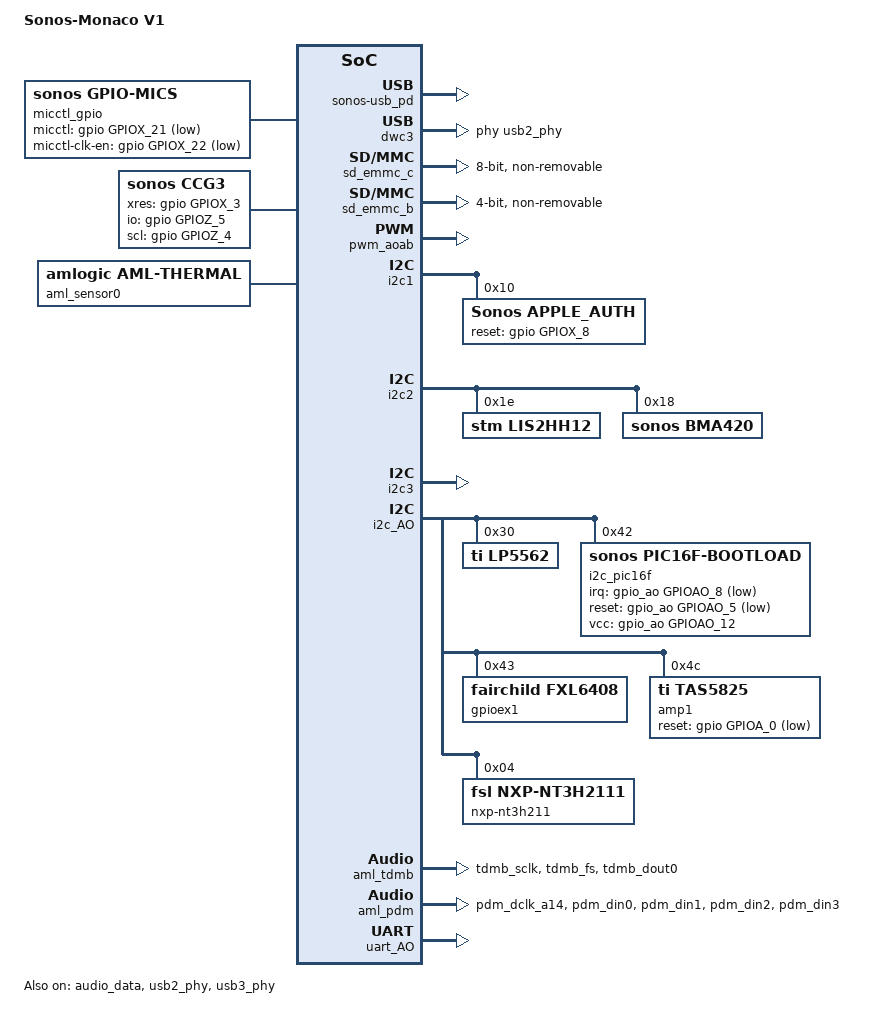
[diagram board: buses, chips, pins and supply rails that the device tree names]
/*
 * Copyright (c) 2019-2020, Sonos, Inc.
 *
 * SPDX-License-Identifier:     GPL-2.0
 */
/* Monaco HW versions
 *      V0 - monaco_v0.dts		- Monaco P0 [Ryles XI]
 *      V1 - monaco.dts			- Monaco P1
 */
/dts-v1/;

#include "a113.dtsi"
#include "../sonos_platform.dtsi"

/ {
	model = "Sonos-Monaco V1";
	amlogic-dt-id = "axg_a113d_skt_v1";
	compatible = "amlogic, axg";
	interrupt-parent = <&gic>;
	#address-cells = <2>;
	#size-cells = <2>;

	sonos-product-id = <0x0d>;

	sonos-platform {
		/* Sonos platform specific values for shared driver source & binaries */
		sonos-ampctl {
			/* Alpine has one amp fault.  It has three control lines.
			 */
			status = "okay";
			hw-inits-index = <1>;
			hw-exits-index = <1>;
			using-i2c-amp;
			ignore-startup-faults;
			allow-auto-recovery;
			supports-boost-control;

			sonos-ampfaults {
				num-faults = <0x01>;
				status = "okay";

				ampfault@0 {
					fault-gpio = <&gpio GPIOA_1 GPIO_ACTIVE_LOW>;
					fault-flags = <IRQ_TYPE_EDGE_FALLING>;
					fault-label = "Amp fault";
				} ;
			} ;
		} ;

		sonos-usb_pd {
			status = "okay";
			hw-inits-index = <1>;
			hw-exits-index = <1>;
		};

		misc-gpio {
			buttons-on-expander;
			no-irq;
		};

		simulated-buttons {
		/* event-sources are offsets from EVTSOURCE_BUTTON_PLAYPAUSE, some generate an event for more than one source */
			join {
				event-sources = <3>;
			};
			mode {
				event-sources = <4>;
			};
			power {
				event-sources= <5>;
				no-repeat-sim;
			};
		};
		thermal-mgmt {
			POWER {
				compatible = "sonos,battery";
				fault-temperature = <68>;
				warn-temperature = <63>;
			};
		};
	} ;

	micctl_gpio:sonos-gpio-micctl {
		compatible = "sonos,gpio-mics";
		micctl-gpio = <&gpio GPIOX_21 GPIO_ACTIVE_LOW>;
		micctl-clk-en = <&gpio GPIOX_22 GPIO_ACTIVE_LOW>;
	};

	micctl@1 {
		compatible = "sonos,micctl";
		micctl-device = <&micctl_gpio>;
	};

	rtc{
		status = "disabled";
	};

	sonos-rtc {
		compatible = "sonos,rtc";
		status = "okay";
	};

	sonos-lla {
		compatible = "sonos,alsa-lla";
		tx_mask = <0x3>;
		rx_mask = <0x7>;
		status = "disabled";
	};

	hrtimer-a113 {
		compatible = "sonos,hrtimer-a113";
		status = "okay";
	};

	ccg3 {
		compatible = "sonos,ccg3";
		xres-gpio = <&gpio GPIOX_3 GPIO_ACTIVE_HIGH>;
		io-gpio   = <&gpio GPIOZ_5 GPIO_ACTIVE_HIGH>;
		scl-gpio  = <&gpio GPIOZ_4 GPIO_ACTIVE_HIGH>;
	};

	aliases {
		serial0 = &uart_AO;
		serial1 = &uart_AO_B;
		serial3 = &uart_A;
	};

	memory@00000000 {
		device_type = "memory";
		linux,usable-memory = <0x0 0x100000 0x0 0x1ff00000>;
	};

	reserved-memory {
		#address-cells = <2>;
		#size-cells = <2>;
		ranges;
		/* global autoconfigured region for contiguous allocations */
		ramoops@0x07400000 {
			compatible = "ramoops";
			reg = <0x0 0x07400000 0x0 0x00100000>;
			record-size = <0x8000>;
			console-size = <0x10000>;
			ftrace-size = <0x2000>;
			pmsg-size = <0x4000>;
		};
		secmon_reserved:linux,secmon {
			compatible = "shared-dma-pool";
			reusable;
			size = <0x0 0x400000>;
			alignment = <0x0 0x400000>;
			alloc-ranges = <0x0 0x05000000 0x0 0x400000>;
		};
		secos_reserved:linux,secos {
			status = "disable";
			compatible = "amlogic, aml_secos_memory";
			reg = <0x0 0x05300000 0x0 0x2000000>;
			no-map;
		};
	};

	ethmac: ethernet@0xff3f0000 {
			compatible = "amlogic, gxbb-eth-dwmac";
			status = "disable";
			reg = <0x0 0xff3f0000 0x0 0x10000
			0x0 0xff634540 0x0 0x8>;
			interrupts = <0 8 1>;
			pinctrl-names = "external_eth_pins";
			pinctrl-0 = <&external_eth_pins>;
			mc_val_internal_phy = <0x1800>;
			mc_val_external_phy = <0x1404>;
			interrupt-names = "macirq";
			clocks = <&clkc CLKID_ETH_CORE>;
			clock-names = "ethclk81";
			internal_phy=<0>;
	};

	aml_sensor0: aml-sensor@0 {
		compatible = "amlogic, aml-thermal";
		device_name = "thermal";
		#thermal-sensor-cells = <1>;
		cooling_devices {
			cpufreq_cool_cluster0 {
				min_state = <1000000>;
				dyn_coeff = <140>;
				cluster_id = <0>;
				node_name = "cpufreq_cool0";
				device_type = "cpufreq";
			};
			cpucore_cool_cluster0 {
				min_state = <1>;
				dyn_coeff = <0>;
				cluster_id = <0>;
				node_name = "cpucore_cool0";
				device_type = "cpucore";
			};
		};
		cpufreq_cool0:cpufreq_cool0 {
			#cooling-cells = <2>; /* min followed by max */
		};
		cpucore_cool0:cpucore_cool0 {
			#cooling-cells = <2>; /* min followed by max */
		};
	};

	remote:rc@0xff808040 {
		status = "disabled";
	};

	thermal-zones {
		soc_thermal {
			polling-delay = <1000>;
			polling-delay-passive = <100>;
			sustainable-power = <1050>;

			thermal-sensors = <&aml_sensor0 3>;

			trips {
				switch_on: trip-point@0 {
					temperature = <70000>;
					hysteresis = <1000>;
					type = "passive";
				};
				control: trip-point@1 {
					temperature = <80000>;
					hysteresis = <1000>;
					type = "passive";
				};
				hot: trip-point@2 {
					temperature = <105000>;
					hysteresis = <5000>;
					type = "hot";
				};
				critical: trip-point@3 {
					temperature = <260000>;
					hysteresis = <1000>;
					type = "critical";
				};
			};

			cooling-maps {
				cpufreq_cooling_map {
					trip = <&control>;
					cooling-device = <&cpufreq_cool0 0 4>;
					contribution = <1024>;
				};
				cpucore_cooling_map {
					trip = <&control>;
					cooling-device = <&cpucore_cool0 0 3>;
					contribution = <1024>;
				};
			};
		};
	};

	dwc3: dwc3@ff500000 {
		compatible = "synopsys, dwc3";
		status = "okay";
		reg = <0x0 0xff500000 0x0 0x100000>;
		interrupts = <0 30 4>;
		usb-phy = <&usb2_phy>, <&usb3_phy>;
		cpu-type = "gxl";
		clock-src = "usb3.0";
		clocks = <&clkc CLKID_USB_GENERAL>;
		clock-names = "dwc_general";
	};

	usb2_phy: usb2phy@ffe09000 {
		compatible = "amlogic, amlogic-new-usb2";
		status = "okay";
		portnum = <4>;
		reg = <0x0 0xffe09000 0x0 0x80>;
	};
	usb3_phy: usb3phy@ffe09080 {
		compatible = "amlogic, amlogic-new-usb3";
		status = "okay";
		portnum = <0>;
		reg = <0x0 0xffe09080 0x0 0x20>;
	};

	dwc2_a {
		compatible = "amlogic, dwc2";
		device_name = "dwc2_a";
		reg = <0x0 0xff400000 0x0 0x40000>;
		status = "disabled";
		interrupts = <0 31 4>;
		pl-periph-id = <0>; /** lm name */
		clock-src = "usb0"; /** clock src */
		port-id = <0>;  /** ref to mach/usb.h */
		port-type = <2>;        /** 0: otg, 1: host, 2: slave */
		port-speed = <0>; /** 0: default, high, 1: full */
		port-config = <0>; /** 0: default */
		/*0:default,1:single,2:incr,3:incr4,4:incr8,5:incr16,6:disable*/
		port-dma = <0>;
		port-id-mode = <0>; /** 0: hardware, 1: sw_host, 2: sw_slave*/
		usb-fifo = <728>;
		cpu-type = "gxl";
		/** 0: normal, 1: otg+dwc3 host only, 2: otg+dwc3 device only*/
		controller-type = <3>;
		phy-reg = <0xffe09000>;
		phy-reg-size = <0xa0>;
		clocks = <&clkc CLKID_USB_GENERAL
			&clkc CLKID_USB1_TO_DDR
			&clkc CLKID_USB1>;
		clock-names = "usb_general",
			"usb1",
			"usb1_to_ddr";
	};

	pcie_A: pcieA@f9800000 {
		compatible = "amlogic, amlogic-pcie", "snps,dw-pcie";
		reg = <0x0 0xf9800000 0x0 0x400000
				0x0 0xff646000 0x0 0x2000
				0x0 0xf9f00000 0x0 0x100000
				0x0 PCIE_PHY_REG 0x0 PCIE_PHY_SIZE
				0x0 PCIE_RESET_REG 0x0 PCIE_RESET_SIZE>;
		reg-names = "elbi", "cfg", "config", "phy", "reset";
		reset-gpio = <&gpio_ao GPIOAO_3 GPIO_ACTIVE_HIGH>;
		interrupts = <0 177 0>, <0 179 0>;
		#interrupt-cells = <1>;
		bus-range = <0x0 0xff>;
		#address-cells = <3>;
		#size-cells = <2>;
		device_type = "pci";
		ranges = <0x82000000 0 0 0x0 0xf9c00000 0 0x00300000>;
			/* non-prefetchable memory */
		num-lanes = <1>;
		pcie-num = <1>;
		speed-mod = <1>; /* gen1 */

		clocks = <&clkc CLKID_USB_GENERAL
				&clkc CLKID_PCIE_PLL
				&clkc CLKID_MIPI_ENABLE_GATE
				&clkc CLKID_MIPI_BANDGAP_GATE
				&clkc CLKID_PCIE_A
				&clkc CLKID_PCIE_CML_EN0>;
		clock-names = "pcie_general",
				"pcie_refpll",
				"pcie_mipi_enable_gate",
				"pcie_mipi_bandgap_gate",
				"pcie",
				"port";
		/*reset-gpio-type 0:Shared pad(no reset)1:OD pad2:Normal pad*/
		gpio-type = <2>;
		status = "disabled";
	};

	pcie_B: pcieB@fa000000 {
		compatible = "amlogic, amlogic-pcie", "snps,dw-pcie";
		reg = <0x0 0xfa000000 0x0 0x400000
				0x0 0xff648000 0x0 0x2000
				0x0 0xfa400000 0x0 0x100000
				0x0 PCIE_PHY_REG 0x0 PCIE_PHY_SIZE
				0x0 PCIE_RESET_REG 0x0 PCIE_RESET_SIZE>;
		reg-names = "elbi", "cfg", "config", "phy", "reset";
		reset-gpio = <&gpio GPIOX_19 GPIO_ACTIVE_HIGH>;
		interrupts = <0 167 0>, <0 169 0>;
		#interrupt-cells = <1>;
		bus-range = <0x0 0xff>;
		#address-cells = <3>;
		#size-cells = <2>;
		device_type = "pci";
		ranges = <0x81000000 0 0 0 0xfa500000 0x0 0x10000
			/* downstream I/O */
			0x82000000 0 0xfa510000 0x0 0xfa510000 0 0x002f0000>;
			/* non-prefetchable memory */
		num-lanes = <1>;
		pcie-num = <2>;
		speed-mod = <1>; /* gen1 */

		clocks = <&clkc CLKID_USB_GENERAL
			&clkc CLKID_PCIE_PLL
			&clkc CLKID_MIPI_ENABLE_GATE
			&clkc CLKID_MIPI_BANDGAP_GATE
			&clkc CLKID_PCIE_B
			&clkc CLKID_PCIE_CML_EN1>;
		clock-names = "pcie_general",
			"pcie_refpll",
			"pcie_mipi_enable_gate",
			"pcie_mipi_bandgap_gate",
			"pcie",
			"port";
		/*reset-gpio-type 0:Shared pad(no reset)1:OD pad2:Normal pad*/
		gpio-type = <0>;
		status = "disabled";
	};

	uart_A: serial@ffd24000 {
		compatible = "amlogic, meson-uart";
		reg = <0x0 0xffd24000 0x0 0x18>;
		interrupts = <0 26 1>;
		status = "disable";
		clocks = <&xtal
			&clkc CLKID_UART0>;
		clock-names = "clk_uart",
			"clk_gate";
		fifosize = < 128 >;
		pinctrl-names = "default";
		pinctrl-0 = <&a_uart_pins>;
	};

	/* Sound iomap */
	aml_snd_iomap {
		compatible = "amlogic, snd-iomap";
		status = "okay";
		#address-cells=<2>;
		#size-cells=<2>;
		ranges;
		pdm_bus {
			reg = <0x0 0xFF632000 0x0 0x2000>;
		};
		audiobus_base {
			reg = <0x0 0xFF642000 0x0 0x2000>;
		};
		audiolocker_base {
			reg = <0x0 0xFF64A000 0x0 0x2000>;
		};
	};
	pdm_codec:dummy{
		#sound-dai-cells = <0>;
		compatible = "amlogic, pdm_dummy_codec";
		status = "okay";
	};
	dummy_codec:dummy{
		#sound-dai-cells = <0>;
		compatible = "amlogic, aml_dummy_codec";
		status = "okay";
	};
	sonos_dummy_codec_dac: dac_dummy_codec {
		#sound-dai-cells = <0>;
		compatible = "Sonos,dummy-codec";
		stream-name = "0-dac";
		rate = <44100>; /* We use 44.1 KHz as the audio output rate */
		format = "S32_LE"; /* We use signed 24-bit little endian samples in a 32-bit word */
		channels = <2>; /* Number of playback channels on Dhuez is 2 */
		status = "okay";
	};
	sonos_dummy_codec_pdm: pdm_dummy_codec {
		#sound-dai-cells = <0>;
		compatible = "Sonos,dummy-codec";
		stream-name = "1-mic";
		rate = <48000>; /* >20 KHz bandwidth required to support "Swap" ultrasonic processing */
		format = "S32_LE"; /* We use signed 24-bit little endian samples in 32-bit words */
		channels = <4>; /* Number of capture channels on Monaco is 4 */
		capture; /* Set the stream direction to capture. Note: Deafult without this boolean flag is playback */
		status = "okay";
	};

	auge_sound {
		compatible = "amlogic, axg-sound-card";
		aml-audio-card,name = "AML-AUGESOUND";

		aml-audio-card,dai-link@1 {
			format = "i2s";
			mclk-fs = <256>;
			continuous-clock;
			frame-inversion;
			bitclock-master = <&aml_tdmb>;
			frame-master = <&aml_tdmb>;
			cpu {
				sound-dai = <&aml_tdmb>;
				dai-tdm-slot-tx-mask = <1 1>;
				dai-tdm-slot-num = <2>;
				dai-tdm-slot-width = <32>;
				system-clock-frequency = <12288000>;
			};
			codec {
				prefix-names = "Sonos i2s out";
				sound-dai = <&sonos_dummy_codec_dac>;
			};
		};

		aml-audio-card,dai-link@3 {
			mclk-fs = <256>;
			cpu {
				sound-dai = <&aml_pdm>;
			};
			codec {
				prefix-names = "Sonos PDM in";
				sound-dai = <&sonos_dummy_codec_pdm>;
			};
		};
	};

	sd_emmc_c: emmc@ffe07000 {
		status = "okay";
		compatible = "amlogic, meson-mmc-axg";
		reg = <0x0 0xffe07000 0x0 0x2000>;
		interrupts = <0 218 1>;
		pinctrl-names = "emmc_clk_cmd_pins", "emmc_all_pins";
		pinctrl-0 = <&emmc_clk_cmd_pins>;
		pinctrl-1 = <&emmc_conf_pull_up &emmc_conf_pull_done>;
		clocks = <&clkc CLKID_SD_EMMC_C>,
			   <&clkc CLKID_SD_EMMC_C_P0_COMP>,
			   <&clkc CLKID_FCLK_DIV2>,
			   <&clkc CLKID_FCLK_DIV5>,
			   <&xtal>;
		clock-names = "core", "clkin0", "clkin1", "clkin2", "xtal";

		bus-width = <8>;
		cap-sd-highspeed;
		cap-mmc-highspeed;
		mmc-ddr-1_8v;
		mmc-hs200-1_8v;

		max-frequency = <200000000>;
		non-removable;
		disable-wp;
		emmc {
			status = "disable";
			pinname = "emmc";
			ocr_avail = <0x200080>; /* VDD voltage 3.3 ~ 3.4 */
			caps = "MMC_CAP_8_BIT_DATA",
				 "MMC_CAP_MMC_HIGHSPEED",
				 "MMC_CAP_SD_HIGHSPEED",
				 "MMC_CAP_NONREMOVABLE",
				 "MMC_CAP_1_8V_DDR",
				 "MMC_CAP_HW_RESET",
				 "MMC_CAP_ERASE",
				 "MMC_CAP_CMD23";
			/* caps2 = "MMC_CAP2_HS200", "MMC_CAP2_HS400"; */
			f_min = <400000>;
			f_max = <200000000>;
			max_req_size = <0x20000>; /* 128KB*/
			gpio_dat3 = <&gpio BOOT_3 GPIO_ACTIVE_HIGH>;
			tx_delay = <0>;
			hw_reset = <&gpio BOOT_9 GPIO_ACTIVE_HIGH>;
			card_type = <1>;
			/* 1:mmc card(include eMMC),
			 * 2:sd card(include tSD)
			 */
		};
	};

	sd_emmc_b:sdio@ffe05000 {
                status = "okay";
                compatible = "amlogic, meson-mmc-axg";
		                reg = <0x0 0xffe05000 0x0 0x2000>;
                interrupts = <0 217 4>;
                pinctrl-names = "sdio_clk_cmd_pins",
                                "sdio_all_pins";
                pinctrl-0 = <&sdio_clk_cmd_pins>;
                pinctrl-1 = <&sdio_all_pins>;
		clocks = <&clkc CLKID_SD_EMMC_B>,
                           <&clkc CLKID_SD_EMMC_B_P0_COMP>,
                           <&clkc CLKID_FCLK_DIV2>,
                           <&clkc CLKID_FCLK_DIV5>,
                           <&xtal>;
                clock-names = "core", "clkin0", "clkin1", "clkin2", "xtal";

                bus-width = <4>;
                cap-sd-highspeed;
                cap-mmc-highspeed;
                max-frequency = <100000000>;
                non-removable;
                disable-wp;
                sdio {
                        pinname = "sdio";
                        ocr_avail = <0x200080>; /**VDD voltage 3.3 ~ 3.4 */
                        caps = "MMC_CAP_4_BIT_DATA",
                                 "MMC_CAP_MMC_HIGHSPEED",
                                 "MMC_CAP_SD_HIGHSPEED",
                                 "MMC_CAP_NONREMOVABLE",
                                 "MMC_CAP_UHS_SDR12",
                                 "MMC_CAP_UHS_SDR25",
                                 "MMC_CAP_UHS_SDR50",
                                 "MMC_CAP_UHS_SDR104",
                                 "MMC_PM_KEEP_POWER",
                                 "MMC_CAP_SDIO_IRQ";
                        f_min = <400000>;
                        f_max = <200000000>;
                        max_req_size = <0x20000>; /**128KB*/
			hw_reset = <&gpio_ao GPIOAO_6 GPIO_ACTIVE_LOW>;
                        card_type = <3>;
                        /* 3:sdio device(ie:sdio-wifi),
                         * 4:SD combo (IO+mem) card
                         */
		};
        };

	/* WiFi */
	mediatek,mt7663-wifi {
                compatible = "mediatek,mt7663_wifi_ctrl";
                interrupts = <&gpio_ao GPIOAO_6 GPIO_ACTIVE_LOW>;
                status = "okay";
	};

	pic16f@0 {
                compatible = "Sonos,pic16f";
                i2c_bus = <2>;
                i2c_reg = <0x42>;
                image-name = "pic16f_v1.hex";
                status = "okay";

		pic16f-gpio@0 {
			icsp-gpio-mclr = <&gpio_ao GPIOAO_5 GPIO_ACTIVE_HIGH>;
			icsp-gpio-data = <&gpio GPIOZ_9 GPIO_ACTIVE_HIGH>;
			icsp-gpio-clk  = <&gpio GPIOZ_8 GPIO_ACTIVE_HIGH>;
		};
        };

	pwm_aoab: pwm@ff807000 {
		status = "okay";
	};

	sonos_pwm_boost {
		/* boost enable circuit for Monaco's amp */
		pinctrl-names = "default";
		pinctrl-0 = <&boost_pwm_pins>;
		pwms = <&pwm_aoab MESON_PWM_0 40000 0>;
		duty-cycle = <15020>;
		boost-gpio = <&gpio GPIOZ_0 GPIO_ACTIVE_HIGH>;
	};

}; /* end of / */

/* Auth chip is alone on this bus, because when it's reset, the bus doesn't work */
&i2c1 {
	status = "okay";
	pinctrl-names="default";
	pinctrl-0=<&b_i2c_master_pin1>;

	apple_auth@0 {
		compatible = "Sonos,apple_auth";
		reg = <0x10>;
		reset-gpio = <&gpio GPIOX_8 GPIO_ACTIVE_HIGH>;
	};

};

&i2c2 {
	status = "okay";

        lis2hh12@0 { // accelerometer
                compatible = "stm,lis2hh12";
		motion-detection-mode;
		music-impacts-z-axis;
                reg = <0x1e>;
                status = "okay";
        };

	bma420@0 { // accelerometer
		compatible = "sonos,bma420";
		reg = <0x18>;
		motion-detection-mode;
		supports-thermal-mgmt;
		music-impacts-z-axis;
		status = "okay";
	};
};

&i2c3 {
	status = "okay";
	pinctrl-names="default";
	pinctrl-0=<&d_i2c_master_pin2>;
};

/* for mic board */
&i2c_AO {
	status = "okay";
	pinctrl-names="default";
	pinctrl-0=<&ao_i2c_master_pin2>;

        lp5562@0 {      // LED controller
                compatible = "ti,lp5562";
                reg = <0x30>;
        };

        i2c_pic16f: pic16f@0 { // PIC16f I2C
                compatible = "sonos,pic16f-bootload";
                reg = <0x42>;
                status = "okay";
                irq-gpio  = <&gpio_ao GPIOAO_8 GPIO_ACTIVE_LOW>;
                reset-gpio = <&gpio_ao GPIOAO_5 GPIO_ACTIVE_LOW>;
                vcc-gpio = <&gpio_ao GPIOAO_12 GPIO_ACTIVE_HIGH>;
                support-rtc;
        };

	gpioex1: fxl6408@43 {	// GPIO expander
		compatible = "fairchild,fxl6408";
		reg = <0x43>;
		num-buttons = <0x04>;
		/* EVTSOURCE index */
		button-source = <0x10 0x09 0x07 0x8>;
                io-dir-init = <0x00>;
                pdnpup-init = <0xff>;
                pull-enable-init = <0xff>;
                input-status-mask = <0x0f>;
                input-default = <0x0f>;
                interrupt-mask = <0xf0>;
		status = "okay";

                fxl6408-int@0 {
			int-gpio = <&gpio GPIOZ_4 GPIO_ACTIVE_LOW>;
			int-flags = <IRQ_TYPE_EDGE_FALLING>;
			int-label = "Button press";
		};
	};

	amp1: tas5825@4c {	// Single amp, dual-channel
		compatible = "ti,tas5825";
		reg = <0x4c>;
		dev-id = <0x2>;
		sleep-to-play-delay = <5>;
		play-to-sleep-delay = <200>;
		post-reset-delay = <10>;
		post-pause-delay = <6>;
		stage-delay = <5>;
		skip-fault-reset;
		mask-clock-faults;
		/*hwalpine-410-fix;*/
		reset-gpio = <&gpio GPIOA_0 GPIO_ACTIVE_LOW>;
		first-amp-devid = <2>;
		/* removed stage 2 by renumbering it to 5, and 3 to 2, which changed the number of stages from 3 to 2.
		 * this needs to be revisited and fixed - https://jira.sonos.com/browse/SWPBL-140032
		 */
		number-init-stages = <3>;
		init-sequence-length1 = <11>;
		reg-init1 = <0x00 0x00 0x7f 0x00 0x03 0x02 0x01 0x11 0x00 0x00 0x00 0x00 0x00 0x00 0x00 0x00 0x00 0x00 0x7f 0x00 0x03 0x02>;
		init-sequence-length2 = <6041>;
		reg-init2 = < 0x00 0x00 0x7f 0x00 0x03 0x02 0x01 0x11 0x00 0x00 0x00 0x00 0x00 0x00 0x00 0x00 0x00 0x00 0x7f 0x00 0x03 0x02 0x00 0x00
			0x00 0x00 0x00 0x00 0x00 0x00 0x00 0x00 0x7f 0x00 0x03 0x12 0x00 0x00 0x00 0x00 0x00 0x00 0x00 0x00 0x00 0x00 0x7f 0x00
			0x48 0x0c 0x00 0x00 0x7f 0x64 0x00 0x01 0x08 0x00 0x09 0xfe 0x0a 0x00 0x0b 0x40 0x0c 0x00 0x0d 0xfc 0x0e 0x00 0x0f 0x00
			0x10 0x00 0x11 0xfc 0x12 0x00 0x13 0x00 0x14 0x00 0x15 0xfc 0x16 0x00 0x17 0x00 0x18 0x00 0x19 0xfc 0x1a 0x00 0x1b 0x00
			0x1c 0x00 0x1d 0xfc 0x1e 0x00 0x1f 0x00 0x20 0x00 0x21 0xfc 0x22 0x00 0x23 0x00 0x24 0x00 0x25 0xfc 0x26 0x00 0x27 0x00
			0x28 0x00 0x29 0xfc 0x2a 0x50 0x2b 0x00 0x2c 0x00 0x2d 0xfc 0x2e 0x00 0x2f 0x00 0x30 0x00 0x31 0xfc 0x32 0x00 0x33 0x00
			0x34 0x00 0x35 0xfc 0x36 0x00 0x37 0x00 0x38 0x00 0x39 0xfc 0x3a 0x00 0x3b 0x00 0x3c 0x00 0x3d 0xfc 0x3e 0x00 0x3f 0x00
			0x40 0x00 0x41 0xfc 0x42 0x00 0x43 0x00 0x44 0x00 0x45 0xfc 0x46 0x00 0x47 0x00 0x48 0x00 0x49 0xfc 0x4a 0x00 0x4b 0x00
			0x4c 0x00 0x4d 0xfc 0x4e 0x00 0x4f 0x00 0x50 0x00 0x51 0xfc 0x52 0x00 0x53 0x00 0x54 0x00 0x55 0xfc 0x56 0x00 0x57 0x00
			0x58 0x00 0x59 0xfc 0x5a 0x00 0x5b 0x00 0x5c 0x00 0x5d 0xfc 0x5e 0x00 0x5f 0x00 0x60 0x00 0x61 0xfc 0x62 0x00 0x63 0x00
			0x64 0x00 0x65 0xfc 0x66 0x00 0x67 0x00 0x68 0x00 0x69 0x82 0x6a 0x00 0x6b 0x93 0x6c 0x00 0x6d 0xfc 0x6e 0x00 0x6f 0x00
			0x70 0x02 0x71 0x70 0x72 0x00 0x73 0x06 0x74 0x02 0x75 0x60 0x76 0x00 0x77 0x01 0x78 0x84 0x79 0xc9 0x7a 0x02 0x7b 0xbd
			0x7c 0x84 0x7d 0x41 0x7e 0x03 0x7f 0x2d 0x00 0x02 0x08 0x84 0x09 0x49 0x0a 0x03 0x0b 0x2e 0x0c 0x8f 0x0d 0x00 0x0e 0xff
			0x0f 0xf8 0x10 0x02 0x11 0x78 0x12 0x00 0x13 0x05 0x14 0x02 0x15 0x68 0x16 0x00 0x17 0x02 0x18 0x02 0x19 0x28 0x1a 0x00
			0x1b 0x03 0x1c 0x84 0x1d 0x02 0x1e 0x04 0x1f 0x04 0x20 0xe2 0x21 0x57 0x22 0x91 0x23 0x9e 0x24 0x84 0x25 0x82 0x26 0x00
			0x27 0xe0 0x28 0x84 0x29 0xca 0x2a 0x20 0x2b 0xe0 0x2c 0xf0 0x2d 0x1c 0x2e 0x11 0x2f 0x9f 0x30 0xf0 0x31 0x1c 0x32 0x11
			0x33 0xa0 0x34 0xf0 0x35 0x1c 0x36 0x11 0x37 0xa1 0x38 0xf0 0x39 0x1f 0x3a 0x11 0x3b 0xa2 0x3c 0xe4 0x3d 0x00 0x3e 0x11
			0x3f 0xa5 0x40 0x80 0x41 0x27 0x42 0x80 0x43 0xe0 0x44 0xf4 0x45 0x00 0x46 0x11 0x47 0xa3 0x48 0xf4 0x49 0x1d 0x4a 0x11
			0x4b 0xa4 0x4c 0xf4 0x4d 0x1c 0x4e 0x11 0x4f 0xa6 0x50 0xf4 0x51 0x1f 0x52 0x11 0x53 0xa7 0x54 0x80 0x55 0x47 0x56 0x80
			0x57 0x82 0x58 0x0c 0x59 0x1d 0x5a 0x0b 0x5b 0x44 0x5c 0x84 0x5d 0xd3 0x5e 0x03 0x5f 0x45 0x60 0x84 0x61 0x43 0x62 0x03
			0x63 0x2d 0x64 0xe0 0x65 0x10 0x66 0x31 0x67 0x9e 0x68 0xf0 0x69 0x1c 0x6a 0x31 0x6b 0x9f 0x6c 0xf0 0x6d 0x1c 0x6e 0x31
			0x6f 0xa0 0x70 0xf0 0x71 0x1c 0x72 0x31 0x73 0xa1 0x74 0xf0 0x75 0x1f 0x76 0x31 0x77 0xa2 0x78 0xe4 0x79 0x00 0x7a 0x11
			0x7b 0xa5 0x7c 0x80 0x7d 0x27 0x7e 0x80 0x7f 0xe1 0x00 0x03 0x08 0xf4 0x09 0x00 0x0a 0x11 0x0b 0xa3 0x0c 0xf4 0x0d 0x1d
			0x0e 0x31 0x0f 0xa4 0x10 0xf4 0x11 0x1c 0x12 0x31 0x13 0xa6 0x14 0xf4 0x15 0x1f 0x16 0x31 0x17 0xa7 0x18 0x80 0x19 0x47
			0x1a 0x80 0x1b 0x82 0x1c 0x0c 0x1d 0x1d 0x1e 0x2b 0x1f 0x45 0x20 0x84 0x21 0xd3 0x22 0x03 0x23 0x67 0x24 0x86 0x25 0xd1
			0x26 0x01 0x27 0xeb 0x28 0x84 0x29 0x4b 0x2a 0x03 0x2b 0x2e 0x2c 0xe0 0x2d 0x10 0x2e 0x31 0x2f 0xe5 0x30 0xe4 0x31 0x10
			0x32 0x00 0x33 0x00 0x34 0xee 0x35 0x68 0x36 0x20 0x37 0x00 0x38 0x02 0x39 0xc3 0x3a 0x00 0x3b 0x10 0x3c 0xea 0x3d 0x68
			0x3e 0x40 0x3f 0x00 0x40 0x02 0x41 0xdb 0x42 0x00 0x43 0x10 0x44 0x88 0x45 0x47 0x46 0x00 0x47 0x81 0x48 0x09 0x49 0x07
			0x4a 0x08 0x4b 0x88 0x4c 0x08 0x4d 0xfc 0x4e 0x28 0x4f 0x71 0x50 0x84 0x51 0xcb 0x52 0x03 0x53 0x42 0x54 0x0d 0x55 0x00
			0x56 0x10 0x57 0x20 0x58 0x08 0x59 0x60 0x5a 0x06 0x5b 0x11 0x5c 0x84 0x5d 0xc3 0x5e 0x03 0x5f 0x41 0x60 0x84 0x61 0x80
			0x62 0x02 0x63 0x00 0x64 0xe0 0x65 0x00 0x66 0x00 0x67 0x81 0x68 0x02 0x69 0x28 0x6a 0x00 0x6b 0x02 0x6c 0x84 0x6d 0x82
			0x6e 0x04 0x6f 0x02 0x70 0x86 0x71 0xc9 0x72 0x01 0x73 0xec 0x74 0x48 0x75 0x47 0x76 0x22 0x77 0x00 0x78 0x80 0x79 0x08
			0x7a 0x00 0x7b 0x80 0x7c 0x08 0x7d 0xfc 0x7e 0x1c 0x7f 0x33 0x00 0x04 0x08 0x0d 0x09 0x00 0x0a 0x10 0x0b 0x10 0x0c 0x84
			0x0d 0xa2 0x0e 0x04 0x0f 0x03 0x10 0x00 0x11 0xfc 0x12 0x00 0x13 0x00 0x14 0x02 0x15 0x83 0x16 0x00 0x17 0x1b 0x18 0x00
			0x19 0x62 0x1a 0x20 0x1b 0x65 0x1c 0x86 0x1d 0xd9 0x1e 0x01 0x1f 0xee 0x20 0x0d 0x21 0x00 0x22 0x10 0x23 0x08 0x24 0x86
			0x25 0xc1 0x26 0x01 0x27 0xe9 0x28 0x86 0x29 0xc9 0x2a 0x01 0x2b 0xea 0x2c 0x00 0x2d 0xfe 0x2e 0x20 0x2f 0x6a 0x30 0x08
			0x31 0x44 0x32 0x26 0x33 0x30 0x34 0x08 0x35 0xfc 0x36 0x1c 0x37 0x51 0x38 0x86 0x39 0xc1 0x3a 0x01 0x3b 0xe8 0x3c 0x86
			0x3d 0xd9 0x3e 0x01 0x3f 0xed 0x40 0x00 0x41 0xfc 0x42 0x00 0x43 0x00 0x44 0x02 0x45 0x83 0x46 0x00 0x47 0x19 0x48 0x02
			0x49 0x28 0x4a 0x00 0x4b 0x01 0x4c 0xe0 0x4d 0x00 0x4e 0x00 0x4f 0x80 0x50 0x88 0x51 0x00 0x52 0x00 0x53 0x81 0x54 0x08
			0x55 0xfc 0x56 0x28 0x57 0x72 0x58 0x84 0x59 0x80 0x5a 0x02 0x5b 0x00 0x5c 0xe0 0x5d 0x00 0x5e 0x00 0x5f 0x82 0x60 0x88
			0x61 0x88 0x62 0x00 0x63 0x83 0x64 0x84 0x65 0xd1 0x66 0x03 0x67 0x43 0x68 0x86 0x69 0xc1 0x6a 0x01 0x6b 0xe6 0x6c 0x86
			0x6d 0xc9 0x6e 0x01 0x6f 0xe7 0x70 0x0d 0x71 0x00 0x72 0x10 0x73 0x70 0x74 0x08 0x75 0x44 0x76 0x26 0x77 0x30 0x78 0x84
			0x79 0x82 0x7a 0x04 0x7b 0x05 0x7c 0x84 0x7d 0x49 0x7e 0x03 0x7f 0x3f 0x00 0x05 0x08 0x84 0x09 0xc9 0x0a 0x02 0x0b 0xbd
			0x0c 0x84 0x0d 0x41 0x0e 0x03 0x0f 0x40 0x10 0x00 0x11 0xfc 0x12 0x00 0x13 0x00 0x14 0xe0 0x15 0x10 0x16 0x60 0x17 0x80
			0x18 0xe8 0x19 0x10 0x1a 0x40 0x1b 0x00 0x1c 0x88 0x1d 0x07 0x1e 0x00 0x1f 0x80 0x20 0x08 0x21 0xfc 0x22 0x08 0x23 0x50
			0x24 0xe2 0x25 0x57 0x26 0x91 0x27 0xc7 0x28 0x84 0x29 0xc3 0x2a 0x03 0x2b 0x43 0x2c 0x84 0x2d 0x82 0x2e 0x20 0x2f 0xe0
			0x30 0xf0 0x31 0x1c 0x32 0x31 0x33 0xc8 0x34 0xf0 0x35 0x1c 0x36 0x31 0x37 0xc9 0x38 0xf0 0x39 0x1c 0x3a 0x31 0x3b 0xca
			0x3c 0xf0 0x3d 0x1f 0x3e 0x31 0x3f 0xcb 0x40 0xe4 0x41 0x00 0x42 0x11 0x43 0xce 0x44 0x80 0x45 0x27 0x46 0x80 0x47 0xe1
			0x48 0xf4 0x49 0x00 0x4a 0x11 0x4b 0xcc 0x4c 0xf4 0x4d 0x1d 0x4e 0x31 0x4f 0xcd 0x50 0xf4 0x51 0x1c 0x52 0x31 0x53 0xcf
			0x54 0xf4 0x55 0x1f 0x56 0x31 0x57 0xd0 0x58 0x80 0x59 0x47 0x5a 0x80 0x5b 0x83 0x5c 0x0c 0x5d 0x1d 0x5e 0x2b 0x5f 0x66
			0x60 0x84 0x61 0xdb 0x62 0x03 0x63 0x6f 0x64 0xe0 0x65 0x10 0x66 0x31 0x67 0xc7 0x68 0x84 0x69 0xca 0x6a 0x00 0x6b 0xe0
			0x6c 0xf0 0x6d 0x1c 0x6e 0x11 0x6f 0xc8 0x70 0xf0 0x71 0x1c 0x72 0x11 0x73 0xc9 0x74 0xf0 0x75 0x1c 0x76 0x11 0x77 0xca
			0x78 0xf0 0x79 0x1f 0x7a 0x11 0x7b 0xcb 0x7c 0xe4 0x7d 0x00 0x7e 0x11 0x7f 0xce 0x00 0x06 0x08 0x80 0x09 0x27 0x0a 0x80
			0x0b 0xe0 0x0c 0xf4 0x0d 0x00 0x0e 0x11 0x0f 0xcc 0x10 0xf4 0x11 0x1d 0x12 0x11 0x13 0xcd 0x14 0xf4 0x15 0x1c 0x16 0x11
			0x17 0xcf 0x18 0xf4 0x19 0x1f 0x1a 0x11 0x1b 0xd0 0x1c 0xe0 0x1d 0x10 0x1e 0x51 0x1f 0xf9 0x20 0x80 0x21 0x47 0x22 0x80
			0x23 0x81 0x24 0x0c 0x25 0x1d 0x26 0x0b 0x27 0x26 0x28 0x84 0x29 0xcb 0x2a 0x03 0x2b 0x7f 0x2c 0xe4 0x2d 0x10 0x2e 0x40
			0x2f 0x00 0x30 0xee 0x31 0x6f 0x32 0x80 0x33 0x00 0x34 0x02 0x35 0xcb 0x36 0x00 0x37 0x10 0x38 0x86 0x39 0xc3 0x3a 0x01
			0x3b 0x9c 0x3c 0xea 0x3d 0x6f 0x3e 0x60 0x3f 0x00 0x40 0x02 0x41 0xc3 0x42 0x00 0x43 0x10 0x44 0x88 0x45 0x47 0x46 0x00
			0x47 0x82 0x48 0x09 0x49 0x07 0x4a 0x09 0x4b 0x31 0x4c 0x08 0x4d 0xfc 0x4e 0x48 0x4f 0x10 0x50 0x84 0x51 0xcb 0x52 0x03
			0x53 0x7c 0x54 0x0d 0x55 0x00 0x56 0x10 0x57 0x20 0x58 0x08 0x59 0x60 0x5a 0x06 0x5b 0x11 0x5c 0x84 0x5d 0x80 0x5e 0x04
			0x5f 0x02 0x60 0xe0 0x61 0x00 0x62 0x00 0x63 0x81 0x64 0x84 0x65 0xa0 0x66 0x04 0x67 0x03 0x68 0x48 0x69 0x47 0x6a 0x20
			0x6b 0x00 0x6c 0x84 0x6d 0xc3 0x6e 0x03 0x6f 0x7b 0x70 0x80 0x71 0x08 0x72 0x00 0x73 0x80 0x74 0x86 0x75 0xd1 0x76 0x01
			0x77 0xff 0x78 0x86 0x79 0xc9 0x7a 0x02 0x7b 0x00 0x7c 0x0d 0x7d 0x00 0x7e 0x10 0x7f 0x10 0x00 0x07 0x08 0x08 0x09 0xfc
			0x0a 0x1c 0x0b 0x33 0x0c 0x84 0x0d 0x4b 0x0e 0x03 0x0f 0x3f 0x10 0x84 0x11 0x43 0x12 0x03 0x13 0x40 0x14 0x84 0x15 0xda
			0x16 0x04 0x17 0x06 0x18 0x00 0x19 0x62 0x1a 0x20 0x1b 0xbf 0x1c 0x86 0x1d 0xd9 0x1e 0x02 0x1f 0x02 0x20 0x0d 0x21 0x00
			0x22 0x10 0x23 0x08 0x24 0x86 0x25 0xc1 0x26 0x01 0x27 0xfd 0x28 0x86 0x29 0xc9 0x2a 0x01 0x2b 0xfe 0x2c 0x00 0x2d 0xfe
			0x2e 0x20 0x2f 0xc3 0x30 0x08 0x31 0x44 0x32 0x26 0x33 0x30 0x34 0x08 0x35 0xfc 0x36 0x1c 0x37 0x51 0x38 0x86 0x39 0xc1
			0x3a 0x01 0x3b 0xfc 0x3c 0x84 0x3d 0xca 0x3e 0x04 0x3f 0x06 0x40 0x86 0x41 0xd9 0x42 0x02 0x43 0x01 0x44 0x84 0x45 0x80
			0x46 0x04 0x47 0x06 0x48 0xe0 0x49 0x00 0x4a 0x00 0x4b 0x80 0x4c 0x88 0x4d 0x00 0x4e 0x00 0x4f 0x80 0x50 0x08 0x51 0xfc
			0x52 0x08 0x53 0x72 0x54 0x84 0x55 0x80 0x56 0x04 0x57 0x05 0x58 0xe0 0x59 0x00 0x5a 0x00 0x5b 0x82 0x5c 0x88 0x5d 0x88
			0x5e 0x00 0x5f 0x83 0x60 0x84 0x61 0xd1 0x62 0x03 0x63 0x7d 0x64 0x86 0x65 0xc1 0x66 0x01 0x67 0xfa 0x68 0x86 0x69 0xc9
			0x6a 0x01 0x6b 0xfb 0x6c 0x0d 0x6d 0x00 0x6e 0x10 0x6f 0x70 0x70 0x08 0x71 0x44 0x72 0x26 0x73 0x30 0x74 0x02 0x75 0x70
			0x76 0x00 0x77 0x0a 0x78 0xe0 0x79 0x10 0x7a 0x60 0x7b 0x80 0x7c 0xe8 0x7d 0x10 0x7e 0x40 0x7f 0x00 0x00 0x08 0x08 0x88
			0x09 0x07 0x0a 0x00 0x0b 0x80 0x0c 0x84 0x0d 0x41 0x0e 0x03 0x0f 0x2f 0x10 0x08 0x11 0xfc 0x12 0x08 0x13 0x50 0x14 0xe2
			0x15 0x57 0x16 0x91 0x17 0xd1 0x18 0x84 0x19 0xc9 0x1a 0x02 0x1b 0xbd 0x1c 0x84 0x1d 0xc3 0x1e 0x03 0x1f 0x7d 0x20 0x84
			0x21 0x82 0x22 0x00 0x23 0xe0 0x24 0xf0 0x25 0x1c 0x26 0x11 0x27 0xd2 0x28 0xf0 0x29 0x1c 0x2a 0x11 0x2b 0xd3 0x2c 0x02
			0x2d 0x78 0x2e 0x00 0x2f 0x09 0x30 0xf0 0x31 0x1c 0x32 0x11 0x33 0xd4 0x34 0xf0 0x35 0x1f 0x36 0x11 0x37 0xd5 0x38 0xe4
			0x39 0x00 0x3a 0x11 0x3b 0xd8 0x3c 0x80 0x3d 0x27 0x3e 0x80 0x3f 0xe0 0x40 0xf4 0x41 0x00 0x42 0x11 0x43 0xd6 0x44 0xf4
			0x45 0x1d 0x46 0x11 0x47 0xd7 0x48 0xf4 0x49 0x1c 0x4a 0x11 0x4b 0xd9 0x4c 0xf4 0x4d 0x1f 0x4e 0x11 0x4f 0xda 0x50 0xe0
			0x51 0x00 0x52 0x11 0x53 0xdd 0x54 0x80 0x55 0x67 0x56 0x80 0x57 0xe0 0x58 0xf0 0x59 0x00 0x5a 0x11 0x5b 0xdb 0x5c 0xf0
			0x5d 0x1d 0x5e 0x11 0x5f 0xdc 0x60 0xf0 0x61 0x1c 0x62 0x11 0x63 0xde 0x64 0xf0 0x65 0x1f 0x66 0x11 0x67 0xdf 0x68 0xe4
			0x69 0x00 0x6a 0x11 0x6b 0xe2 0x6c 0x80 0x6d 0x27 0x6e 0x80 0x6f 0xe0 0x70 0xf4 0x71 0x00 0x72 0x11 0x73 0xe0 0x74 0xf4
			0x75 0x1d 0x76 0x11 0x77 0xe1 0x78 0xf4 0x79 0x1c 0x7a 0x11 0x7b 0xe3 0x7c 0xf4 0x7d 0x1f 0x7e 0x11 0x7f 0xe4 0x00 0x09
			0x08 0x80 0x09 0x47 0x0a 0x80 0x0b 0x83 0x0c 0x84 0x0d 0x49 0x0e 0x03 0x0f 0x37 0x10 0x0c 0x11 0x1d 0x12 0x0b 0x13 0x66
			0x14 0x84 0x15 0xdb 0x16 0x03 0x17 0x8b 0x18 0xe0 0x19 0x10 0x1a 0x31 0x1b 0xd1 0x1c 0x84 0x1d 0xca 0x1e 0x20 0x1f 0xe0
			0x20 0xf0 0x21 0x1c 0x22 0x31 0x23 0xd2 0x24 0xf0 0x25 0x1c 0x26 0x31 0x27 0xd3 0x28 0xf0 0x29 0x1c 0x2a 0x31 0x2b 0xd4
			0x2c 0xf0 0x2d 0x1f 0x2e 0x31 0x2f 0xd5 0x30 0xe4 0x31 0x00 0x32 0x11 0x33 0xd8 0x34 0x80 0x35 0x27 0x36 0x80 0x37 0xe1
			0x38 0xf4 0x39 0x00 0x3a 0x11 0x3b 0xd6 0x3c 0xf4 0x3d 0x1d 0x3e 0x31 0x3f 0xd7 0x40 0xf4 0x41 0x1c 0x42 0x31 0x43 0xd9
			0x44 0xf4 0x45 0x1f 0x46 0x31 0x47 0xda 0x48 0xe0 0x49 0x00 0x4a 0x11 0x4b 0xdd 0x4c 0x80 0x4d 0x67 0x4e 0x80 0x4f 0xe1
			0x50 0xf0 0x51 0x00 0x52 0x11 0x53 0xdb 0x54 0xf0 0x55 0x1d 0x56 0x31 0x57 0xdc 0x58 0xf0 0x59 0x1c 0x5a 0x31 0x5b 0xde
			0x5c 0xf0 0x5d 0x1f 0x5e 0x31 0x5f 0xdf 0x60 0xe4 0x61 0x00 0x62 0x11 0x63 0xe2 0x64 0x80 0x65 0x27 0x66 0x80 0x67 0xe1
			0x68 0xf4 0x69 0x00 0x6a 0x11 0x6b 0xe0 0x6c 0xf4 0x6d 0x1d 0x6e 0x31 0x6f 0xe1 0x70 0xf4 0x71 0x1c 0x72 0x31 0x73 0xe3
			0x74 0xf4 0x75 0x1f 0x76 0x31 0x77 0xe4 0x78 0xe0 0x79 0x10 0x7a 0x51 0x7b 0xef 0x7c 0x80 0x7d 0x47 0x7e 0x80 0x7f 0x81
			0x00 0x0a 0x08 0x0c 0x09 0x1d 0x0a 0x2b 0x0b 0x26 0x0c 0x84 0x0d 0xcb 0x0e 0x03 0x0f 0x8c 0x10 0xe4 0x11 0x10 0x12 0x40
			0x13 0x00 0x14 0xee 0x15 0x6c 0x16 0x80 0x17 0x00 0x18 0x02 0x19 0xcb 0x1a 0x00 0x1b 0x10 0x1c 0x86 0x1d 0xc3 0x1e 0x01
			0x1f 0x9b 0x20 0xea 0x21 0x6c 0x22 0x60 0x23 0x00 0x24 0x02 0x25 0xc3 0x26 0x00 0x27 0x10 0x28 0x88 0x29 0x47 0x2a 0x00
			0x2b 0x82 0x2c 0x09 0x2d 0x07 0x2e 0x09 0x2f 0x31 0x30 0x08 0x31 0xfc 0x32 0x48 0x33 0x10 0x34 0x84 0x35 0xcb 0x36 0x03
			0x37 0x64 0x38 0x0d 0x39 0x00 0x3a 0x10 0x3b 0x20 0x3c 0x08 0x3d 0x60 0x3e 0x06 0x3f 0x11 0x40 0x84 0x41 0x80 0x42 0x04
			0x43 0x02 0x44 0xe0 0x45 0x00 0x46 0x00 0x47 0x81 0x48 0x84 0x49 0xa0 0x4a 0x04 0x4b 0x03 0x4c 0x48 0x4d 0x47 0x4e 0x20
			0x4f 0x00 0x50 0x84 0x51 0xc3 0x52 0x03 0x53 0x63 0x54 0x80 0x55 0x08 0x56 0x00 0x57 0x80 0x58 0x86 0x59 0xd1 0x5a 0x01
			0x5b 0xf5 0x5c 0x86 0x5d 0xc9 0x5e 0x01 0x5f 0xf6 0x60 0x0d 0x61 0x00 0x62 0x10 0x63 0x10 0x64 0x08 0x65 0xfc 0x66 0x1c
			0x67 0x33 0x68 0x84 0x69 0x43 0x6a 0x03 0x6b 0x2f 0x6c 0x84 0x6d 0x4b 0x6e 0x03 0x6f 0x37 0x70 0x84 0x71 0xda 0x72 0x04
			0x73 0x02 0x74 0x00 0x75 0x62 0x76 0x21 0x77 0x32 0x78 0x86 0x79 0xd9 0x7a 0x01 0x7b 0xf8 0x7c 0x0d 0x7d 0x00 0x7e 0x10
			0x7f 0x08 0x00 0x0b 0x08 0x02 0x09 0x50 0x0a 0x02 0x0b 0xbc 0x0c 0x02 0x0d 0x48 0x0e 0x02 0x0f 0xbd 0x10 0x86 0x11 0xc1
			0x12 0x01 0x13 0xf3 0x14 0x86 0x15 0xc9 0x16 0x01 0x17 0xf4 0x18 0x00 0x19 0xfe 0x1a 0x21 0x1b 0x38 0x1c 0x08 0x1d 0x44
			0x1e 0x26 0x1f 0x30 0x20 0x08 0x21 0xfc 0x22 0x1c 0x23 0x51 0x24 0x86 0x25 0xc1 0x26 0x01 0x27 0xf2 0x28 0x84 0x29 0xca
			0x2a 0x04 0x2b 0x02 0x2c 0x02 0x2d 0x50 0x2e 0x02 0x2f 0xbc 0x30 0x02 0x31 0x48 0x32 0x02 0x33 0xbd 0x34 0x86 0x35 0xd9
			0x36 0x01 0x37 0xf7 0x38 0xe6 0x39 0x68 0x3a 0xb1 0x3b 0x9c 0x3c 0xe2 0x3d 0x6c 0x3e 0xe0 0x3f 0x00 0x40 0x4d 0x41 0x40
			0x42 0x11 0x43 0xa8 0x44 0x48 0x45 0x40 0x46 0x00 0x47 0x00 0x48 0x88 0x49 0x40 0x4a 0x13 0x4b 0x27 0x4c 0xe6 0x4d 0x6d
			0x4e 0xf1 0x4f 0x9b 0x50 0x88 0x51 0x00 0x52 0x13 0x53 0x2a 0x54 0xe2 0x55 0x6f 0x56 0xe0 0x57 0x00 0x58 0x4d 0x59 0x40
			0x5a 0x11 0x5b 0xaa 0x5c 0x48 0x5d 0x40 0x5e 0x00 0x5f 0x00 0x60 0x88 0x61 0x40 0x62 0x13 0x63 0x29 0x64 0xe4 0x65 0x80
			0x66 0x40 0x67 0x80 0x68 0x88 0x69 0x40 0x6a 0x00 0x6b 0x80 0x6c 0x08 0x6d 0xfc 0x6e 0x08 0x6f 0x71 0x70 0x85 0x71 0x5a
			0x72 0x00 0x73 0x80 0x74 0x88 0x75 0x00 0x76 0x13 0x77 0x2c 0x78 0xe0 0x79 0x80 0x7a 0xa0 0x7b 0x81 0x7c 0x02 0x7d 0xca
			0x7e 0x0f 0x7f 0x80 0x00 0x0c 0x08 0x09 0x09 0x88 0x0a 0x01 0x0b 0x21 0x0c 0x08 0x0d 0xfc 0x0e 0x2a 0x0f 0xfb 0x10 0x84
			0x11 0xc9 0x12 0x03 0x13 0x65 0x14 0x0d 0x15 0x00 0x16 0x10 0x17 0x48 0x18 0x84 0x19 0xc3 0x1a 0x03 0x1b 0xae 0x1c 0x8c
			0x1d 0xff 0x1e 0x04 0x1f 0x80 0x20 0x02 0x21 0x63 0x22 0x00 0x23 0x1b 0x24 0x86 0x25 0xd9 0x26 0x01 0x27 0xf0 0x28 0x84
			0x29 0x84 0x2a 0x09 0x2b 0x00 0x2c 0x02 0x2d 0x83 0x2e 0x00 0x2f 0x1a 0x30 0x86 0x31 0xd1 0x32 0x01 0x33 0xf1 0x34 0x08
			0x35 0x44 0x36 0x46 0x37 0x53 0x38 0x84 0x39 0xd1 0x3a 0x03 0x3b 0xac 0x3c 0x08 0x3d 0xfc 0x3e 0x00 0x3f 0x52 0x40 0x08
			0x41 0xfc 0x42 0x46 0x43 0xfa 0x44 0xe0 0x45 0x00 0x46 0x00 0x47 0x83 0x48 0xe8 0x49 0x10 0x4a 0x20 0x4b 0x00 0x4c 0x88
			0x4d 0x07 0x4e 0x00 0x4f 0x83 0x50 0x08 0x51 0xfc 0x52 0x68 0x53 0x31 0x54 0x84 0x55 0x81 0x56 0x03 0x57 0x8c 0x58 0xe0
			0x59 0x00 0x5a 0x00 0x5b 0x81 0x5c 0xe6 0x5d 0x71 0x5e 0x60 0x5f 0x00 0x60 0x86 0x61 0xa1 0x62 0x01 0x63 0xa9 0x64 0x4d
			0x65 0x40 0x66 0x00 0x67 0x00 0x68 0x48 0x69 0x40 0x6a 0x00 0x6b 0x00 0x6c 0x88 0x6d 0x40 0x6e 0x13 0x6f 0x28 0x70 0x84
			0x71 0xcb 0x72 0x03 0x73 0x65 0x74 0x86 0x75 0xcb 0x76 0x01 0x77 0x9d 0x78 0x84 0x79 0xc9 0x7a 0x03 0x7b 0xab 0x7c 0x88
			0x7d 0x20 0x7e 0x13 0x7f 0x2b 0x00 0x0d 0x08 0x08 0x09 0xfc 0x0a 0x00 0x0b 0x33 0x0c 0x84 0x0d 0xc1 0x0e 0x03 0x0f 0x28
			0x10 0x84 0x11 0xc9 0x12 0x03 0x13 0x27 0x14 0x08 0x15 0xfc 0x16 0x28 0x17 0x10 0x18 0x02 0x19 0xcb 0x1a 0x00 0x1b 0x10
			0x1c 0xe0 0x1d 0x20 0x1e 0x00 0x1f 0x82 0x20 0x84 0x21 0xd1 0x22 0x03 0x23 0x2a 0x24 0x08 0x25 0xfc 0x26 0x48 0x27 0x32
			0x28 0x84 0x29 0xc9 0x2a 0x03 0x2b 0x29 0x2c 0x0c 0x2d 0xa0 0x2e 0x08 0x2f 0x20 0x30 0x84 0x31 0xc1 0x32 0x03 0x33 0x2c
			0x34 0x0c 0x35 0x60 0x36 0x08 0x37 0x10 0x38 0x08 0x39 0xfc 0x3a 0x66 0x3b 0x7b 0x3c 0x86 0x3d 0xc9 0x3e 0x01 0x3f 0xab
			0x40 0x84 0x41 0xdb 0x42 0x03 0x43 0x9b 0x44 0x84 0x45 0x63 0x46 0x03 0x47 0xad 0x48 0x02 0x49 0x40 0x4a 0x03 0x4b 0xa3
			0x4c 0x88 0x4d 0x27 0x4e 0x73 0x4f 0x9a 0x50 0x00 0x51 0xff 0x52 0x11 0x53 0x4e 0x54 0x02 0x55 0xc3 0x56 0x00 0x57 0x10
			0x58 0x02 0x59 0x40 0x5a 0x03 0x5b 0xa2 0x5c 0x84 0x5d 0xc1 0x5e 0x03 0x5f 0x9b 0x60 0x86 0x61 0xc9 0x62 0x01 0x63 0xac
			0x64 0x00 0x65 0xff 0x66 0x11 0x67 0x4e 0x68 0x00 0x69 0xfc 0x6a 0x00 0x6b 0x00 0x6c 0x02 0x6d 0x40 0x6e 0x03 0x6f 0xa3
			0x70 0x02 0x71 0x48 0x72 0x03 0x73 0xa2 0x74 0x02 0x75 0x50 0x76 0x03 0x77 0xa1 0x78 0x00 0x79 0xff 0x7a 0x11 0x7b 0x55
			0x7c 0x00 0x7d 0xfc 0x7e 0x00 0x7f 0x00 0x00 0x0e 0x08 0x02 0x09 0x50 0x0a 0x02 0x0b 0xbd 0x0c 0x02 0x0d 0xc0 0x0e 0x03
			0x0f 0xa1 0x10 0x84 0x11 0x52 0x12 0x04 0x13 0x00 0x14 0x8e 0x15 0xfd 0x16 0x02 0x17 0xbc 0x18 0x84 0x19 0xc2 0x1a 0x04
			0x1b 0x01 0x1c 0x00 0x1d 0xff 0x1e 0x10 0x1f 0xb0 0x20 0x8c 0x21 0xfe 0x22 0x21 0x23 0x00 0x24 0x02 0x25 0x48 0x26 0x01
			0x27 0xb1 0x28 0x02 0x29 0x40 0x2a 0x03 0x2b 0x46 0x2c 0x84 0x2d 0xc1 0x2e 0x02 0x2f 0xbc 0x30 0x84 0x31 0xc9 0x32 0x02
			0x33 0xbd 0x34 0x00 0x35 0xff 0x36 0x22 0x37 0xb2 0x38 0x00 0x39 0xfc 0x3a 0x00 0x3b 0x00 0x3c 0x86 0x3d 0xc9 0x3e 0x01
			0x3f 0xad 0x40 0x08 0x41 0x00 0x42 0x10 0x43 0x20 0x44 0x00 0x45 0xfc 0x46 0x00 0x47 0x00 0x48 0x00 0x49 0xfc 0x4a 0x00
			0x4b 0x00 0x4c 0x00 0x4d 0x26 0x4e 0x21 0x4f 0xa8 0x50 0x84 0x51 0xc3 0x52 0x02 0x53 0xbe 0x54 0x02 0x55 0x40 0x56 0x03
			0x57 0x8d 0x58 0x84 0x59 0xc1 0x5a 0x02 0x5b 0xbc 0x5c 0x00 0x5d 0xff 0x5e 0x22 0x5f 0x9e 0x60 0x00 0x61 0xfc 0x62 0x00
			0x63 0x00 0x64 0x86 0x65 0xc9 0x66 0x01 0x67 0xad 0x68 0x84 0x69 0xc3 0x6a 0x02 0x6b 0xbc 0x6c 0x02 0x6d 0x40 0x6e 0x03
			0x6f 0x8e 0x70 0x00 0x71 0xff 0x72 0x22 0x73 0x9e 0x74 0x00 0x75 0xfc 0x76 0x00 0x77 0x00 0x78 0x86 0x79 0xc9 0x7a 0x01
			0x7b 0xad 0x7c 0x84 0x7d 0xc3 0x7e 0x02 0x7f 0xbc 0x00 0x0f 0x08 0x02 0x09 0x40 0x0a 0x03 0x0b 0x8f 0x0c 0x00 0x0d 0xff
			0x0e 0x22 0x0f 0x9e 0x10 0x00 0x11 0xfc 0x12 0x00 0x13 0x00 0x14 0x84 0x15 0xc3 0x16 0x02 0x17 0xbc 0x18 0x86 0x19 0xc9
			0x1a 0x01 0x1b 0xae 0x1c 0x08 0x1d 0x00 0x1e 0x10 0x1f 0x20 0x20 0x00 0x21 0xfc 0x22 0x00 0x23 0x00 0x24 0x00 0x25 0xfc
			0x26 0x00 0x27 0x00 0x28 0x00 0x29 0x26 0x2a 0x21 0x2b 0xbd 0x2c 0x00 0x2d 0xfc 0x2e 0x00 0x2f 0x00 0x30 0x02 0x31 0x40
			0x32 0x03 0x33 0x97 0x34 0x84 0x35 0xc1 0x36 0x02 0x37 0xbd 0x38 0x00 0x39 0xff 0x3a 0x22 0x3b 0xa8 0x3c 0x00 0x3d 0xfc
			0x3e 0x00 0x3f 0x00 0x40 0x86 0x41 0xc9 0x42 0x01 0x43 0xae 0x44 0x84 0x45 0xc3 0x46 0x02 0x47 0xbd 0x48 0x02 0x49 0x40
			0x4a 0x03 0x4b 0x98 0x4c 0x00 0x4d 0xff 0x4e 0x22 0x4f 0xa8 0x50 0x00 0x51 0xfc 0x52 0x00 0x53 0x00 0x54 0x86 0x55 0xc9
			0x56 0x01 0x57 0xae 0x58 0x84 0x59 0xc3 0x5a 0x02 0x5b 0xbd 0x5c 0x02 0x5d 0x40 0x5e 0x03 0x5f 0x99 0x60 0x00 0x61 0xff
			0x62 0x22 0x63 0xa8 0x64 0x00 0x65 0xfc 0x66 0x00 0x67 0x00 0x68 0x84 0x69 0xc3 0x6a 0x02 0x6b 0xbd 0x6c 0x84 0x6d 0xa1
			0x6e 0x03 0x6f 0x9a 0x70 0x84 0x71 0x81 0x72 0x03 0x73 0x26 0x74 0xe0 0x75 0x00 0x76 0x00 0x77 0x00 0x78 0x84 0x79 0x81
			0x7a 0x03 0x7b 0x23 0x7c 0xe4 0x7d 0x00 0x7e 0x00 0x7f 0x00 0x00 0x10 0x08 0x84 0x09 0x81 0x0a 0x03 0x0b 0x24 0x0c 0x84
			0x0d 0xc1 0x0e 0x02 0x0f 0xbd 0x10 0x86 0x11 0x05 0x12 0x02 0x13 0x03 0x14 0x88 0x15 0x07 0x16 0x00 0x17 0x82 0x18 0xe0
			0x19 0x00 0x1a 0x00 0x1b 0x00 0x1c 0x08 0x1d 0xfc 0x1e 0x04 0x1f 0x98 0x20 0x84 0x21 0x06 0x22 0x04 0x23 0x05 0x24 0x08
			0x25 0x00 0x26 0x0a 0x27 0x00 0x28 0x84 0x29 0xa2 0x2a 0x04 0x2b 0x03 0x2c 0x84 0x2d 0xa0 0x2e 0x04 0x2f 0x05 0x30 0x88
			0x31 0x47 0x32 0x04 0x33 0x02 0x34 0xe4 0x35 0x10 0x36 0x00 0x37 0x00 0x38 0xee 0x39 0x74 0x3a 0xa0 0x3b 0x00 0x3c 0x84
			0x3d 0x82 0x3e 0x04 0x3f 0x06 0x40 0x84 0x41 0x81 0x42 0x03 0x43 0x25 0x44 0x84 0x45 0xc9 0x46 0x02 0x47 0xbc 0x48 0x08
			0x49 0xfc 0x4a 0x24 0x4b 0x99 0x4c 0x04 0x4d 0x80 0x4e 0x4a 0x4f 0xa3 0x50 0x88 0x51 0x47 0x52 0x04 0x53 0x07 0x54 0x84
			0x55 0xa0 0x56 0x04 0x57 0x03 0x58 0xe4 0x59 0x00 0x5a 0x00 0x5b 0x00 0x5c 0x02 0x5d 0x83 0x5e 0x00 0x5f 0x1b 0x60 0x02
			0x61 0xdb 0x62 0x00 0x63 0x1a 0x64 0x84 0x65 0xc1 0x66 0x03 0x67 0xa8 0x68 0x08 0x69 0x00 0x6a 0x50 0x6b 0x00 0x6c 0xc8
			0x6d 0x27 0x6e 0x00 0x6f 0x81 0x70 0x08 0x71 0x00 0x72 0x50 0x73 0x00 0x74 0xc9 0x75 0x27 0x76 0x00 0x77 0x82 0x78 0x08
			0x79 0x00 0x7a 0x30 0x7b 0x00 0x7c 0xc9 0x7d 0x27 0x7e 0x00 0x7f 0x81 0x00 0x11 0x08 0x08 0x09 0x00 0x0a 0x70 0x0b 0x00
			0x0c 0xc8 0x0d 0x27 0x0e 0x00 0x0f 0x82 0x10 0x08 0x11 0x00 0x12 0x10 0x13 0x00 0x14 0x08 0x15 0x24 0x16 0x66 0x17 0x71
			0x18 0x84 0x19 0xd8 0x1a 0x04 0x1b 0x07 0x1c 0x84 0x1d 0xa0 0x1e 0x04 0x1f 0x05 0x20 0x84 0x21 0xca 0x22 0x04 0x23 0x05
			0x24 0x84 0x25 0xd2 0x26 0x04 0x27 0x03 0x28 0xe0 0x29 0x00 0x2a 0x00 0x2b 0x00 0x2c 0x84 0x2d 0xd0 0x2e 0x04 0x2f 0x06
			0x30 0x08 0x31 0xfc 0x32 0x68 0x33 0x51 0x34 0xea 0x35 0x74 0x36 0x80 0x37 0x00 0x38 0x02 0x39 0xdb 0x3a 0x00 0x3b 0x10
			0x3c 0x88 0x3d 0x07 0x3e 0x00 0x3f 0x82 0x40 0x08 0x41 0xfc 0x42 0x48 0x43 0x72 0x44 0x0d 0x45 0x00 0x46 0x10 0x47 0x30
			0x48 0x84 0x49 0xcb 0x4a 0x03 0x4b 0xa5 0x4c 0x08 0x4d 0x60 0x4e 0x46 0x4f 0x51 0x50 0x08 0x51 0x00 0x52 0x90 0x53 0x00
			0x54 0xe0 0x55 0x10 0x56 0x32 0x57 0x07 0x58 0x84 0x59 0xc8 0x5a 0x04 0x5b 0x02 0x5c 0x84 0x5d 0xc2 0x5e 0x04 0x5f 0x06
			0x60 0x84 0x61 0xd3 0x62 0x03 0x63 0xa4 0x64 0x84 0x65 0xc0 0x66 0x04 0x67 0x03 0x68 0x08 0x69 0x24 0x6a 0x26 0x6b 0x30
			0x6c 0x86 0x6d 0x05 0x6e 0x02 0x6f 0x04 0x70 0x88 0x71 0x00 0x72 0x00 0x73 0x82 0x74 0x0d 0x75 0x00 0x76 0x10 0x77 0x40
			0x78 0x84 0x79 0x06 0x7a 0x04 0x7b 0x07 0x7c 0x84 0x7d 0xc1 0x7e 0x03 0x7f 0xaa 0x00 0x12 0x08 0x84 0x09 0xd9 0x0a 0x03
			0x0b 0xa9 0x0c 0x8c 0x0d 0xff 0x0e 0x03 0x0f 0xa9 0x10 0x00 0x11 0x62 0x12 0x22 0x13 0x0d 0x14 0x02 0x15 0xc8 0x16 0x00
			0x17 0x01 0x18 0x84 0x19 0xc8 0x1a 0x04 0x1b 0x07 0x1c 0x0d 0x1d 0x00 0x1e 0x10 0x1f 0x68 0x20 0x00 0x21 0xfc 0x22 0x00
			0x23 0x00 0x24 0x00 0x25 0xfc 0x26 0x00 0x27 0x00 0x28 0x00 0x29 0x26 0x2a 0x22 0x2b 0x0d 0x2c 0x02 0x2d 0xc8 0x2e 0x00
			0x2f 0x01 0x30 0x08 0x31 0x00 0x32 0x10 0x33 0x00 0x34 0x00 0x35 0xfc 0x36 0x00 0x37 0x00 0x38 0x00 0x39 0xfc 0x3a 0x00
			0x3b 0x00 0x3c 0x00 0x3d 0x26 0x3e 0x22 0x3f 0x10 0x40 0x00 0x41 0xfc 0x42 0x00 0x43 0x00 0x44 0x02 0x45 0xd8 0x46 0x00
			0x47 0x00 0x48 0x00 0x49 0xfe 0x4a 0x22 0x4b 0x11 0x4c 0x84 0x4d 0xdb 0x4e 0x03 0x4f 0xa9 0x50 0x0c 0x51 0x20 0x52 0x0c
			0x53 0x3b 0x54 0x84 0x55 0xd8 0x56 0x04 0x57 0x05 0x58 0x0d 0x59 0x00 0x5a 0x10 0x5b 0x58 0x5c 0x86 0x5d 0xd1 0x5e 0x02
			0x5f 0x05 0x60 0x84 0x61 0xd9 0x62 0x03 0x63 0xa9 0x64 0x00 0x65 0x46 0x66 0x22 0x67 0x21 0x68 0x00 0x69 0xfc 0x6a 0x00
			0x6b 0x00 0x6c 0x0d 0x6d 0x00 0x6e 0x10 0x6f 0x10 0x70 0x00 0x71 0xfc 0x72 0x00 0x73 0x00 0x74 0x00 0x75 0xfc 0x76 0x00
			0x77 0x00 0x78 0x00 0x79 0x26 0x7a 0x22 0x7b 0x21 0x7c 0x00 0x7d 0xfc 0x7e 0x00 0x7f 0x00 0x00 0x13 0x08 0x08 0x09 0x00
			0x0a 0x10 0x0b 0x60 0x0c 0x00 0x0d 0xfc 0x0e 0x00 0x0f 0x00 0x10 0x00 0x11 0xfc 0x12 0x00 0x13 0x00 0x14 0x00 0x15 0x26
			0x16 0x22 0x17 0x24 0x18 0x00 0x19 0xfc 0x1a 0x00 0x1b 0x00 0x1c 0x02 0x1d 0xc0 0x1e 0x00 0x1f 0x00 0x20 0x00 0x21 0xfe
			0x22 0x22 0x23 0x26 0x24 0x84 0x25 0xc3 0x26 0x03 0x27 0xaa 0x28 0x8c 0x29 0xff 0x2a 0x03 0x2b 0xaa 0x2c 0x0c 0x2d 0x20
			0x2e 0x0c 0x2f 0x20 0x30 0x84 0x31 0xc0 0x32 0x04 0x33 0x06 0x34 0x08 0x35 0x00 0x36 0x90 0x37 0x00 0x38 0x00 0x39 0xfc
			0x3a 0x00 0x3b 0x00 0x3c 0x00 0x3d 0xfc 0x3e 0x00 0x3f 0x00 0x40 0x00 0x41 0x26 0x42 0x22 0x43 0x7b 0x44 0x00 0x45 0xfc
			0x46 0x00 0x47 0x00 0x48 0x08 0x49 0x00 0x4a 0x70 0x4b 0x00 0x4c 0x00 0x4d 0xfc 0x4e 0x00 0x4f 0x00 0x50 0x00 0x51 0xfc
			0x52 0x00 0x53 0x00 0x54 0x00 0x55 0x26 0x56 0x22 0x57 0x6a 0x58 0x84 0x59 0xc9 0x5a 0x03 0x5b 0xaa 0x5c 0x08 0x5d 0x00
			0x5e 0x50 0x5f 0x00 0x60 0x00 0x61 0xfc 0x62 0x00 0x63 0x00 0x64 0x00 0x65 0xfc 0x66 0x00 0x67 0x00 0x68 0x00 0x69 0x26
			0x6a 0x22 0x6b 0x59 0x6c 0x00 0x6d 0xfc 0x6e 0x00 0x6f 0x00 0x70 0x08 0x71 0x00 0x72 0x30 0x73 0x00 0x74 0x00 0x75 0xfc
			0x76 0x00 0x77 0x00 0x78 0x00 0x79 0xfc 0x7a 0x00 0x7b 0x00 0x7c 0x00 0x7d 0x26 0x7e 0x22 0x7f 0x48 0x00 0x14 0x08 0x00
			0x09 0xfc 0x0a 0x00 0x0b 0x00 0x0c 0x08 0x0d 0x00 0x0e 0x10 0x0f 0x00 0x10 0x00 0x11 0xfc 0x12 0x00 0x13 0x00 0x14 0x00
			0x15 0xfc 0x16 0x00 0x17 0x00 0x18 0x00 0x19 0x22 0x1a 0x22 0x1b 0x83 0x1c 0x00 0x1d 0xfc 0x1e 0x00 0x1f 0x00 0x20 0x0d
			0x21 0x00 0x22 0x10 0x23 0x30 0x24 0x00 0x25 0xfc 0x26 0x00 0x27 0x00 0x28 0x00 0x29 0xfc 0x2a 0x00 0x2b 0x00 0x2c 0x00
			0x2d 0x22 0x2e 0x22 0x2f 0x83 0x30 0x00 0x31 0xfc 0x32 0x00 0x33 0x00 0x34 0x02 0x35 0xc0 0x36 0x00 0x37 0x01 0x38 0x00
			0x39 0xfe 0x3a 0x22 0x3b 0x83 0x3c 0x84 0x3d 0xc3 0x3e 0x03 0x3f 0xa8 0x40 0x84 0x41 0xc0 0x42 0x04 0x43 0x07 0x44 0x0d
			0x45 0x00 0x46 0x10 0x47 0x60 0x48 0x00 0x49 0xfc 0x4a 0x00 0x4b 0x00 0x4c 0x00 0x4d 0xfc 0x4e 0x00 0x4f 0x00 0x50 0x00
			0x51 0x26 0x52 0x22 0x53 0x56 0x54 0x00 0x55 0xfc 0x56 0x00 0x57 0x00 0x58 0x0d 0x59 0x00 0x5a 0x10 0x5b 0x30 0x5c 0x00
			0x5d 0xfc 0x5e 0x00 0x5f 0x00 0x60 0x00 0x61 0xfc 0x62 0x00 0x63 0x00 0x64 0x00 0x65 0x22 0x66 0x22 0x67 0x83 0x68 0x00
			0x69 0xfc 0x6a 0x00 0x6b 0x00 0x6c 0x02 0x6d 0xc0 0x6e 0x00 0x6f 0x02 0x70 0x00 0x71 0xfe 0x72 0x22 0x73 0x83 0x74 0x84
			0x75 0xc3 0x76 0x03 0x77 0xa8 0x78 0x02 0x79 0xc0 0x7a 0x00 0x7b 0x00 0x7c 0x00 0x7d 0xfe 0x7e 0x22 0x7f 0x83 0x00 0x15
			0x08 0x84 0x09 0xc3 0x0a 0x03 0x0b 0xa8 0x0c 0x84 0x0d 0xc0 0x0e 0x04 0x0f 0x07 0x10 0x0d 0x11 0x00 0x12 0x10 0x13 0x60
			0x14 0x00 0x15 0xfc 0x16 0x00 0x17 0x00 0x18 0x00 0x19 0xfc 0x1a 0x00 0x1b 0x00 0x1c 0x00 0x1d 0x26 0x1e 0x22 0x1f 0x67
			0x20 0x00 0x21 0xfc 0x22 0x00 0x23 0x00 0x24 0x0d 0x25 0x00 0x26 0x10 0x27 0x30 0x28 0x00 0x29 0xfc 0x2a 0x00 0x2b 0x00
			0x2c 0x00 0x2d 0xfc 0x2e 0x00 0x2f 0x00 0x30 0x00 0x31 0x22 0x32 0x22 0x33 0x83 0x34 0x00 0x35 0xfc 0x36 0x00 0x37 0x00
			0x38 0x02 0x39 0xc0 0x3a 0x00 0x3b 0x03 0x3c 0x00 0x3d 0xfe 0x3e 0x22 0x3f 0x83 0x40 0x84 0x41 0xc3 0x42 0x03 0x43 0xa8
			0x44 0x02 0x45 0xc0 0x46 0x00 0x47 0x01 0x48 0x00 0x49 0xfe 0x4a 0x22 0x4b 0x83 0x4c 0x84 0x4d 0xc3 0x4e 0x03 0x4f 0xa8
			0x50 0x84 0x51 0xc0 0x52 0x04 0x53 0x07 0x54 0x0d 0x55 0x00 0x56 0x10 0x57 0x60 0x58 0x00 0x59 0xfc 0x5a 0x00 0x5b 0x00
			0x5c 0x00 0x5d 0xfc 0x5e 0x00 0x5f 0x00 0x60 0x00 0x61 0x26 0x62 0x22 0x63 0x78 0x64 0x00 0x65 0xfc 0x66 0x00 0x67 0x00
			0x68 0x0d 0x69 0x00 0x6a 0x10 0x6b 0x30 0x6c 0x00 0x6d 0xfc 0x6e 0x00 0x6f 0x00 0x70 0x00 0x71 0xfc 0x72 0x00 0x73 0x00
			0x74 0x00 0x75 0x22 0x76 0x22 0x77 0x83 0x78 0x00 0x79 0xfc 0x7a 0x00 0x7b 0x00 0x7c 0x02 0x7d 0xc0 0x7e 0x00 0x7f 0x04
			0x00 0x16 0x08 0x00 0x09 0xfe 0x0a 0x22 0x0b 0x83 0x0c 0x84 0x0d 0xc3 0x0e 0x03 0x0f 0xa8 0x10 0x02 0x11 0xc0 0x12 0x00
			0x13 0x02 0x14 0x00 0x15 0xfe 0x16 0x22 0x17 0x83 0x18 0x84 0x19 0xc3 0x1a 0x03 0x1b 0xa8 0x1c 0x84 0x1d 0xc0 0x1e 0x04
			0x1f 0x07 0x20 0x0d 0x21 0x00 0x22 0x10 0x23 0x60 0x24 0x00 0x25 0xfc 0x26 0x00 0x27 0x00 0x28 0x00 0x29 0xfc 0x2a 0x00
			0x2b 0x00 0x2c 0x00 0x2d 0x22 0x2e 0x22 0x2f 0x83 0x30 0x00 0x31 0xfc 0x32 0x00 0x33 0x00 0x34 0x02 0x35 0xc0 0x36 0x00
			0x37 0x03 0x38 0x84 0x39 0xc3 0x3a 0x03 0x3b 0xa8 0x3c 0x8e 0x3d 0xfd 0x3e 0x03 0x3f 0xa8 0x40 0x02 0x41 0xc0 0x42 0x00
			0x43 0x00 0x44 0x02 0x45 0xd2 0x46 0x08 0x47 0x40 0x48 0x02 0x49 0xda 0x4a 0x10 0x4b 0x80 0x4c 0x04 0x4d 0x60 0x4e 0x11
			0x4f 0x24 0x50 0x84 0x51 0xc9 0x52 0x03 0x53 0xa7 0x54 0x08 0x55 0x24 0x56 0x46 0x57 0x51 0x58 0x02 0x59 0xd0 0x5a 0x00
			0x5b 0x01 0x5c 0x04 0x5d 0x60 0x5e 0x11 0x5f 0x54 0x60 0x08 0x61 0x24 0x62 0x66 0x63 0x71 0x64 0x02 0x65 0xd0 0x66 0x00
			0x67 0x02 0x68 0x02 0x69 0xda 0x6a 0x21 0x6b 0x00 0x6c 0x04 0x6d 0x60 0x6e 0x11 0x6f 0x54 0x70 0x08 0x71 0x24 0x72 0x66
			0x73 0x71 0x74 0x02 0x75 0xd0 0x76 0x00 0x77 0x03 0x78 0x02 0x79 0xda 0x7a 0x42 0x7b 0x00 0x7c 0x04 0x7d 0x60 0x7e 0x11
			0x7f 0x54 0x00 0x17 0x08 0x08 0x09 0x24 0x0a 0x66 0x0b 0x71 0x0c 0x02 0x0d 0xd0 0x0e 0x00 0x0f 0x04 0x10 0x02 0x11 0xda
			0x12 0x84 0x13 0x00 0x14 0x04 0x15 0x60 0x16 0x11 0x17 0x54 0x18 0x84 0x19 0x00 0x1a 0x04 0x1b 0x04 0x1c 0x08 0x1d 0x24
			0x1e 0x66 0x1f 0x71 0x20 0x84 0x21 0xcb 0x22 0x03 0x23 0xa7 0x24 0x84 0x25 0xca 0x26 0x00 0x27 0x4a 0x28 0x00 0x29 0xfc
			0x2a 0x50 0x2b 0x00 0x2c 0x8f 0x2d 0x00 0x2e 0x00 0x2f 0x08 0x30 0x84 0x31 0x48 0x32 0x01 0x33 0x00 0x34 0x00 0x35 0xfc
			0x36 0x00 0x37 0x00 0x38 0x02 0x39 0x73 0x3a 0x00 0x3b 0x19 0x3c 0x02 0x3d 0x28 0x3e 0x00 0x3f 0x01 0x40 0x84 0x41 0xc2
			0x42 0x30 0x43 0x01 0x44 0xe0 0x45 0x60 0x46 0x02 0x47 0x00 0x48 0x84 0x49 0x4a 0x4a 0x01 0x4b 0x00 0x4c 0x80 0x4d 0x07
			0x4e 0x00 0x4f 0x80 0x50 0x00 0x51 0xfc 0x52 0x50 0x53 0x00 0x54 0x00 0x55 0xfc 0x56 0x00 0x57 0x00 0x58 0x84 0x59 0x48
			0x5a 0x01 0x5b 0x00 0x5c 0x00 0x5d 0xfc 0x5e 0x00 0x5f 0x00 0x60 0x02 0x61 0x73 0x62 0x00 0x63 0x19 0x64 0x02 0x65 0x28
			0x66 0x00 0x67 0x01 0x68 0x86 0x69 0xc2 0x6a 0x30 0x6b 0x01 0x6c 0xe0 0x6d 0x40 0x6e 0x03 0x6f 0x00 0x70 0x84 0x71 0x4a
			0x72 0x01 0x73 0x00 0x74 0x80 0x75 0x07 0x76 0x00 0x77 0x80 0x78 0x00 0x79 0xfc 0x7a 0x50 0x7b 0x00 0x7c 0x00 0x7d 0xfc
			0x7e 0x00 0x7f 0x00 0x00 0x18 0x08 0x04 0x09 0x20 0x0a 0x2a 0x0b 0x02 0x0c 0x08 0x0d 0x00 0x0e 0x0a 0x0f 0x21 0x10 0x0d
			0x11 0x00 0x12 0x10 0x13 0x48 0x14 0x08 0x15 0x44 0x16 0x46 0x17 0x51 0x18 0x0c 0x19 0x20 0x1a 0x10 0x1b 0x0c 0x1c 0x8f
			0x1d 0x30 0x1e 0x00 0x1f 0x02 0x20 0x08 0x21 0x44 0x22 0x06 0x23 0x11 0x24 0x84 0x25 0xd0 0x26 0x41 0x27 0x00 0x28 0x06
			0x29 0x60 0x2a 0x30 0x2b 0x44 0x2c 0x84 0x2d 0xca 0x2e 0x01 0x2f 0x01 0x30 0x00 0x31 0xfc 0x32 0x00 0x33 0x00 0x34 0x00
			0x35 0x66 0x36 0x22 0x37 0xc1 0x38 0x02 0x39 0xc0 0x3a 0x00 0x3b 0x01 0x3c 0x00 0x3d 0xfe 0x3e 0x22 0x3f 0xc6 0x40 0x0c
			0x41 0x20 0x42 0x4c 0x43 0x11 0x44 0x02 0x45 0xc8 0x46 0x00 0x47 0x00 0x48 0x84 0x49 0xd0 0x4a 0x01 0x4b 0x01 0x4c 0x84
			0x4d 0xd2 0x4e 0x01 0x4f 0x03 0x50 0x84 0x51 0xca 0x52 0x01 0x53 0x01 0x54 0x84 0x55 0xca 0x56 0x01 0x57 0x02 0x58 0xe0
			0x59 0x20 0x5a 0xc3 0x5b 0x03 0x5c 0x80 0x5d 0x07 0x5e 0x00 0x5f 0x82 0x60 0x84 0x61 0xc8 0x62 0x01 0x63 0x03 0x64 0x0d
			0x65 0x00 0x66 0x10 0x67 0x30 0x68 0x00 0x69 0xfc 0x6a 0x00 0x6b 0x00 0x6c 0x00 0x6d 0xfc 0x6e 0x00 0x6f 0x00 0x70 0x00
			0x71 0x66 0x72 0x22 0x73 0xde 0x74 0x00 0x75 0xfc 0x76 0x00 0x77 0x00 0x78 0x84 0x79 0xd0 0x7a 0x01 0x7b 0x04 0x7c 0x06
			0x7d 0x60 0x7e 0x50 0x7f 0x5c 0x00 0x19 0x08 0x00 0x09 0xfc 0x0a 0x00 0x0b 0x00 0x0c 0x00 0x0d 0xfc 0x0e 0x00 0x0f 0x00
			0x10 0x00 0x11 0x46 0x12 0x22 0x13 0xd6 0x14 0x00 0x15 0xfc 0x16 0x00 0x17 0x00 0x18 0x00 0x19 0xfe 0x1a 0x22 0x1b 0xe1
			0x1c 0x0c 0x1d 0x20 0x1e 0x8c 0x1f 0x11 0x20 0x86 0x21 0xd0 0x22 0x21 0x23 0x04 0x24 0x00 0x25 0xfc 0x26 0x00 0x27 0x00
			0x28 0xe0 0x29 0x00 0x2a 0x00 0x2b 0x82 0x2c 0x80 0x2d 0x07 0x2e 0x00 0x2f 0x82 0x30 0x0d 0x31 0x00 0x32 0x10 0x33 0x30
			0x34 0x08 0x35 0x44 0x36 0x26 0x37 0x32 0x38 0x00 0x39 0xfe 0x3a 0x22 0x3b 0xe1 0x3c 0x84 0x3d 0xd2 0x3e 0x01 0x3f 0x05
			0x40 0x02 0x41 0xd0 0x42 0x00 0x43 0x00 0x44 0x84 0x45 0xca 0x46 0x01 0x47 0x05 0x48 0x84 0x49 0xd2 0x4a 0x01 0x4b 0x04
			0x4c 0x02 0x4d 0x60 0x4e 0x00 0x4f 0x06 0x50 0x8f 0x51 0x70 0x52 0x00 0x53 0x00 0x54 0x86 0x55 0xa0 0x56 0x29 0x57 0x05
			0x58 0xe0 0x59 0x20 0x5a 0xa0 0x5b 0x00 0x5c 0x84 0x5d 0x82 0x5e 0x01 0x5f 0x06 0x60 0xe8 0x61 0x21 0x62 0x00 0x63 0x00
			0x64 0x02 0x65 0xd3 0x66 0x00 0x67 0x10 0x68 0x88 0x69 0x07 0x6a 0x00 0x6b 0x83 0x6c 0x0c 0x6d 0x20 0x6e 0xe8 0x6f 0x5a
			0x70 0x86 0x71 0xd8 0x72 0x21 0x73 0x00 0x74 0x0c 0x75 0x21 0x76 0x11 0x77 0x5c 0x78 0x8f 0x79 0x38 0x7a 0x00 0x7b 0x0c
			0x7c 0x02 0x7d 0xc8 0x7e 0x00 0x7f 0x00 0x00 0x1a 0x08 0x00 0x09 0x46 0x0a 0x23 0x0b 0x6c 0x0c 0x86 0x0d 0xca 0x0e 0x41
			0x0f 0x00 0x10 0x06 0x11 0x60 0x12 0x30 0x13 0x5c 0x14 0x00 0x15 0xfc 0x16 0x00 0x17 0x00 0x18 0x00 0x19 0xfc 0x1a 0x00
			0x1b 0x00 0x1c 0x00 0x1d 0x46 0x1e 0x23 0x1f 0x69 0x20 0x00 0x21 0xfc 0x22 0x00 0x23 0x00 0x24 0x06 0x25 0x60 0x26 0x50
			0x27 0x5c 0x28 0x00 0x29 0xfc 0x2a 0x00 0x2b 0x00 0x2c 0x00 0x2d 0xfc 0x2e 0x00 0x2f 0x00 0x30 0x00 0x31 0x46 0x32 0x23
			0x33 0x66 0x34 0x00 0x35 0xfc 0x36 0x00 0x37 0x00 0x38 0x06 0x39 0x60 0x3a 0x70 0x3b 0x5c 0x3c 0x00 0x3d 0xfc 0x3e 0x00
			0x3f 0x00 0x40 0x00 0x41 0xfc 0x42 0x00 0x43 0x00 0x44 0x00 0x45 0x46 0x46 0x23 0x47 0x63 0x48 0x00 0x49 0xfc 0x4a 0x00
			0x4b 0x00 0x4c 0x06 0x4d 0x60 0x4e 0x90 0x4f 0x5c 0x50 0x00 0x51 0xfc 0x52 0x00 0x53 0x00 0x54 0x00 0x55 0xfc 0x56 0x00
			0x57 0x00 0x58 0x00 0x59 0x46 0x5a 0x23 0x5b 0x60 0x5c 0x00 0x5d 0xfc 0x5e 0x00 0x5f 0x00 0x60 0x06 0x61 0x60 0x62 0xb0
			0x63 0x5c 0x64 0x00 0x65 0xfc 0x66 0x00 0x67 0x00 0x68 0x00 0x69 0xfc 0x6a 0x00 0x6b 0x00 0x6c 0x00 0x6d 0x46 0x6e 0x23
			0x6f 0x5d 0x70 0x00 0x71 0xfc 0x72 0x00 0x73 0x00 0x74 0x06 0x75 0x60 0x76 0xd0 0x77 0x5c 0x78 0x00 0x79 0xfc 0x7a 0x00
			0x7b 0x00 0x7c 0x00 0x7d 0xfc 0x7e 0x00 0x7f 0x00 0x00 0x1b 0x08 0x00 0x09 0x46 0x0a 0x23 0x0b 0x5a 0x0c 0x00 0x0d 0xfc
			0x0e 0x00 0x0f 0x00 0x10 0x06 0x11 0x60 0x12 0xf0 0x13 0x5c 0x14 0x00 0x15 0xfc 0x16 0x00 0x17 0x00 0x18 0x00 0x19 0xfc
			0x1a 0x00 0x1b 0x00 0x1c 0x00 0x1d 0x46 0x1e 0x23 0x1f 0x57 0x20 0x00 0x21 0xfc 0x22 0x00 0x23 0x00 0x24 0x06 0x25 0x61
			0x26 0x10 0x27 0x5c 0x28 0x00 0x29 0xfc 0x2a 0x00 0x2b 0x00 0x2c 0x00 0x2d 0xfc 0x2e 0x00 0x2f 0x00 0x30 0x00 0x31 0x46
			0x32 0x23 0x33 0x54 0x34 0x00 0x35 0xfc 0x36 0x00 0x37 0x00 0x38 0x06 0x39 0x61 0x3a 0x30 0x3b 0x5c 0x3c 0x00 0x3d 0xfc
			0x3e 0x00 0x3f 0x00 0x40 0x00 0x41 0xfc 0x42 0x00 0x43 0x00 0x44 0x00 0x45 0x46 0x46 0x23 0x47 0x51 0x48 0x00 0x49 0xfc
			0x4a 0x00 0x4b 0x00 0x4c 0x06 0x4d 0x61 0x4e 0x50 0x4f 0x5c 0x50 0x00 0x51 0xfc 0x52 0x00 0x53 0x00 0x54 0x00 0x55 0xfc
			0x56 0x00 0x57 0x00 0x58 0x00 0x59 0x46 0x5a 0x23 0x5b 0x4e 0x5c 0x00 0x5d 0xfc 0x5e 0x00 0x5f 0x00 0x60 0x06 0x61 0x61
			0x62 0x70 0x63 0x5c 0x64 0x00 0x65 0xfc 0x66 0x00 0x67 0x00 0x68 0x00 0x69 0xfc 0x6a 0x00 0x6b 0x00 0x6c 0x00 0x6d 0x46
			0x6e 0x23 0x6f 0x4b 0x70 0x00 0x71 0xfc 0x72 0x00 0x73 0x00 0x74 0x06 0x75 0x61 0x76 0x90 0x77 0x5c 0x78 0x00 0x79 0xfc
			0x7a 0x00 0x7b 0x00 0x7c 0x00 0x7d 0xfc 0x7e 0x00 0x7f 0x00 0x00 0x1c 0x08 0x00 0x09 0x46 0x0a 0x23 0x0b 0x48 0x0c 0x00
			0x0d 0xfc 0x0e 0x00 0x0f 0x00 0x10 0x06 0x11 0x61 0x12 0xb0 0x13 0x5c 0x14 0x00 0x15 0xfc 0x16 0x00 0x17 0x00 0x18 0x00
			0x19 0xfc 0x1a 0x00 0x1b 0x00 0x1c 0x00 0x1d 0x46 0x1e 0x23 0x1f 0x45 0x20 0x00 0x21 0xfc 0x22 0x00 0x23 0x00 0x24 0x06
			0x25 0x61 0x26 0xd0 0x27 0x5c 0x28 0x00 0x29 0xfc 0x2a 0x00 0x2b 0x00 0x2c 0x00 0x2d 0xfc 0x2e 0x00 0x2f 0x00 0x30 0x00
			0x31 0x46 0x32 0x23 0x33 0x42 0x34 0x00 0x35 0xfc 0x36 0x00 0x37 0x00 0x38 0x06 0x39 0x61 0x3a 0xf0 0x3b 0x54 0x3c 0x00
			0x3d 0xfc 0x3e 0x00 0x3f 0x00 0x40 0x00 0x41 0xfc 0x42 0x00 0x43 0x00 0x44 0x00 0x45 0x46 0x46 0x23 0x47 0x3f 0x48 0x00
			0x49 0xfc 0x4a 0x00 0x4b 0x00 0x4c 0x84 0x4d 0xd0 0x4e 0x61 0x4f 0x10 0x50 0x86 0x51 0xc2 0x52 0x41 0x53 0x00 0x54 0x00
			0x55 0xfe 0x56 0x23 0x57 0x6e 0x58 0x84 0x59 0xd2 0x5a 0x01 0x5b 0x09 0x5c 0x84 0x5d 0xc0 0x5e 0x61 0x5f 0x0f 0x60 0x00
			0x61 0xfe 0x62 0x23 0x63 0x6e 0x64 0x84 0x65 0xc2 0x66 0x01 0x67 0x09 0x68 0x84 0x69 0xc0 0x6a 0x61 0x6b 0x0e 0x6c 0x00
			0x6d 0xfe 0x6e 0x23 0x6f 0x6e 0x70 0x84 0x71 0xc2 0x72 0x01 0x73 0x09 0x74 0x84 0x75 0xc0 0x76 0x61 0x77 0x0d 0x78 0x00
			0x79 0xfe 0x7a 0x23 0x7b 0x6e 0x7c 0x84 0x7d 0xc2 0x7e 0x01 0x7f 0x09 0x00 0x1d 0x08 0x84 0x09 0xc0 0x0a 0x61 0x0b 0x0c
			0x0c 0x00 0x0d 0xfe 0x0e 0x23 0x0f 0x6e 0x10 0x84 0x11 0xc2 0x12 0x01 0x13 0x09 0x14 0x84 0x15 0xc0 0x16 0x61 0x17 0x0b
			0x18 0x00 0x19 0xfe 0x1a 0x23 0x1b 0x6e 0x1c 0x84 0x1d 0xc2 0x1e 0x01 0x1f 0x09 0x20 0x84 0x21 0xc0 0x22 0x61 0x23 0x0a
			0x24 0x00 0x25 0xfe 0x26 0x23 0x27 0x6e 0x28 0x84 0x29 0xc2 0x2a 0x01 0x2b 0x09 0x2c 0x84 0x2d 0xc0 0x2e 0x61 0x2f 0x09
			0x30 0x00 0x31 0xfe 0x32 0x23 0x33 0x6e 0x34 0x84 0x35 0xc2 0x36 0x01 0x37 0x09 0x38 0x84 0x39 0xc0 0x3a 0x61 0x3b 0x08
			0x3c 0x00 0x3d 0xfe 0x3e 0x23 0x3f 0x6e 0x40 0x84 0x41 0xc2 0x42 0x01 0x43 0x09 0x44 0x84 0x45 0xc0 0x46 0x61 0x47 0x07
			0x48 0x00 0x49 0xfe 0x4a 0x23 0x4b 0x6e 0x4c 0x84 0x4d 0xc2 0x4e 0x01 0x4f 0x09 0x50 0x84 0x51 0xc0 0x52 0x61 0x53 0x06
			0x54 0x00 0x55 0xfe 0x56 0x23 0x57 0x6e 0x58 0x84 0x59 0xc2 0x5a 0x01 0x5b 0x09 0x5c 0x84 0x5d 0xc0 0x5e 0x61 0x5f 0x05
			0x60 0x00 0x61 0xfe 0x62 0x23 0x63 0x6e 0x64 0x84 0x65 0xc2 0x66 0x01 0x67 0x09 0x68 0x84 0x69 0xc0 0x6a 0x61 0x6b 0x04
			0x6c 0x00 0x6d 0xfe 0x6e 0x23 0x6f 0x6e 0x70 0x84 0x71 0xc2 0x72 0x01 0x73 0x09 0x74 0x84 0x75 0xc0 0x76 0x61 0x77 0x03
			0x78 0x00 0x79 0xfe 0x7a 0x23 0x7b 0x6e 0x7c 0x84 0x7d 0xc2 0x7e 0x01 0x7f 0x09 0x00 0x1e 0x08 0x84 0x09 0xc0 0x0a 0x61
			0x0b 0x02 0x0c 0x00 0x0d 0xfe 0x0e 0x23 0x0f 0x6e 0x10 0x84 0x11 0xc2 0x12 0x01 0x13 0x09 0x14 0x84 0x15 0xc0 0x16 0x61
			0x17 0x01 0x18 0x00 0x19 0xfe 0x1a 0x23 0x1b 0x6e 0x1c 0x84 0x1d 0xc2 0x1e 0x01 0x1f 0x09 0x20 0x84 0x21 0xc0 0x22 0x01
			0x23 0x0c 0x24 0x84 0x25 0xc2 0x26 0x01 0x27 0x09 0x28 0x06 0x29 0xa0 0x2a 0x11 0x2b 0x0c 0x2c 0x84 0x2d 0xc0 0x2e 0x01
			0x2f 0x09 0x30 0x00 0x31 0xfc 0x32 0x00 0x33 0x00 0x34 0x02 0x35 0xca 0x36 0x7f 0x37 0x00 0x38 0x02 0x39 0xd2 0x3a 0x01
			0x3b 0x00 0x3c 0x08 0x3d 0x20 0x3e 0x26 0x3f 0x32 0x40 0x84 0x41 0xd2 0x42 0x00 0x43 0x49 0x44 0x00 0x45 0xfc 0x46 0x50
			0x47 0x00 0x48 0x00 0x49 0xfc 0x4a 0x00 0x4b 0x00 0x00 0x00 0x7f 0x78 0x00 0x18 0x30 0x00 0x31 0x00 0x32 0x00 0x33 0x00
			0x34 0x00 0x35 0x00 0x36 0x00 0x37 0x00 0x38 0x00 0x39 0x00 0x3a 0x00 0x3b 0x00 0x3c 0x00 0x3d 0x00 0x3e 0x00 0x3f 0x00
			0x40 0x00 0x41 0x00 0x42 0x00 0x43 0x01 0x00 0x1b 0x64 0x07 0x65 0xae 0x66 0x14 0x67 0x7a 0x68 0x14 0x69 0x7a 0x6a 0xe1
			0x6b 0x47 0x6c 0x21 0x6d 0x47 0x6e 0xae 0x6f 0x14 0x70 0x2e 0x71 0x14 0x72 0x7a 0x73 0xe1 0x00 0x1c 0x14 0x00 0x15 0x00
			0x16 0x03 0x17 0x30 0x18 0x00 0x19 0x00 0x1a 0x03 0x1b 0x38 0x1c 0x00 0x1d 0x00 0x1e 0x03 0x1f 0x70 0x20 0x00 0x21 0x00
			0x22 0x00 0x23 0x00 0x24 0x00 0x25 0x00 0x26 0x00 0x27 0x00 0x28 0x00 0x29 0x00 0x2a 0x00 0x2b 0x00 0x2c 0x00 0x2d 0x00
			0x2e 0x00 0x2f 0x00 0x30 0x00 0x31 0x00 0x32 0x00 0x33 0x00 0x34 0x00 0x35 0x00 0x36 0x00 0x37 0x00 0x38 0x00 0x39 0x00
			0x3a 0x00 0x3b 0x00 0x3c 0x00 0x3d 0x00 0x3e 0x03 0x3f 0x80 0x40 0x00 0x41 0x00 0x42 0x00 0x43 0x00 0x44 0x00 0x45 0x00
			0x46 0x00 0x47 0x00 0x48 0x00 0x49 0x00 0x4a 0x00 0x4b 0x00 0x4c 0x00 0x4d 0x00 0x4e 0x00 0x4f 0x00 0x50 0x00 0x51 0x00
			0x52 0x00 0x53 0x00 0x54 0x00 0x55 0x00 0x56 0x00 0x57 0x00 0x58 0x00 0x59 0x00 0x5a 0x00 0x5b 0x00 0x5c 0x00 0x5d 0x00
			0x5e 0x03 0x5f 0x68 0x60 0x00 0x61 0x00 0x62 0x03 0x63 0x90 0x64 0x00 0x65 0x00 0x66 0x00 0x67 0x00 0x68 0x00 0x69 0x00
			0x6a 0x00 0x6b 0x00 0x6c 0x00 0x6d 0x80 0x6e 0x00 0x6f 0x00 0x70 0x00 0x71 0x00 0x72 0x00 0x73 0x00 0x74 0x00 0x75 0x00
			0x76 0x00 0x77 0x00 0x78 0x00 0x79 0x00 0x7a 0x00 0x7b 0x00 0x7c 0x00 0x7d 0x00 0x7e 0x00 0x7f 0x00 0x00 0x1d 0x08 0x00
			0x09 0x00 0x0a 0x00 0x0b 0x00 0x0c 0x00 0x0d 0x00 0x0e 0x00 0x0f 0x00 0x10 0x00 0x11 0x00 0x12 0x00 0x13 0x00 0x14 0x00
			0x15 0x00 0x16 0x00 0x17 0x00 0x18 0x00 0x19 0x00 0x1a 0x00 0x1b 0x00 0x1c 0x00 0x1d 0x00 0x1e 0x00 0x1f 0x00 0x20 0x00
			0x21 0x00 0x22 0x00 0x23 0x00 0x24 0x00 0x25 0x00 0x26 0x00 0x27 0x00 0x28 0x00 0x29 0x00 0x2a 0x00 0x2b 0x00 0x2c 0x00
			0x2d 0x00 0x2e 0x00 0x2f 0x00 0x30 0x00 0x31 0x00 0x32 0x00 0x33 0x00 0x34 0x00 0x35 0x10 0x36 0x01 0x37 0x00 0x38 0x00
			0x39 0x30 0x3a 0x03 0x3b 0x00 0x3c 0x00 0x3d 0x70 0x3e 0x07 0x3f 0x00 0x40 0x00 0x41 0xf0 0x42 0x0f 0x43 0x00 0x44 0x01
			0x45 0xf0 0x46 0x1f 0x47 0x00 0x48 0x03 0x49 0xf0 0x4a 0x3f 0x4b 0x00 0x4c 0x07 0x4d 0xf0 0x4e 0x7f 0x4f 0x00 0x50 0x07
			0x51 0xf0 0x52 0x7f 0x53 0x00 0x54 0x1f 0x55 0xf1 0x56 0xff 0x57 0x00 0x58 0x3f 0x59 0xf3 0x5a 0xff 0x5b 0x00 0x5c 0x7f
			0x5d 0xf7 0x5e 0xff 0x5f 0x00 0x60 0xff 0x61 0xff 0x62 0xff 0x63 0x00 0x64 0xff 0x65 0xff 0x66 0xff 0x67 0x00 0x68 0xff
			0x69 0xff 0x6a 0xff 0x6b 0x00 0x6c 0xff 0x6d 0xff 0x6e 0xff 0x6f 0x00 0x70 0xff 0x71 0xff 0x72 0xff 0x73 0x00 0x74 0x00
			0x75 0x00 0x76 0x00 0x77 0x00 0x78 0x00 0x79 0x00 0x7a 0x00 0x7b 0x00 0x7c 0x00 0x7d 0x80 0x7e 0x00 0x7f 0x00 0x00 0x1e
			0x08 0x00 0x09 0x00 0x0a 0x00 0x0b 0x00 0x0c 0x00 0x0d 0x00 0x0e 0x00 0x0f 0x00 0x10 0x00 0x11 0x00 0x12 0x00 0x13 0x00
			0x14 0x00 0x15 0x00 0x16 0x00 0x17 0x00 0x18 0x00 0x19 0x00 0x1a 0x00 0x1b 0x00 0x1c 0x00 0x1d 0x00 0x1e 0x00 0x1f 0x00
			0x20 0x00 0x21 0x00 0x22 0x00 0x23 0x00 0x24 0x00 0x25 0x00 0x26 0x00 0x27 0x00 0x28 0x00 0x29 0x00 0x2a 0x00 0x2b 0x00
			0x2c 0x00 0x2d 0x00 0x2e 0x00 0x2f 0x00 0x30 0x00 0x31 0x00 0x32 0x00 0x33 0x00 0x34 0x00 0x35 0x00 0x36 0x00 0x37 0x00
			0x38 0x00 0x39 0x00 0x3a 0x00 0x3b 0x00 0x3c 0x00 0x3d 0x00 0x3e 0x00 0x3f 0x00 0x40 0x00 0x41 0x00 0x42 0x00 0x43 0x00
			0x44 0x00 0x45 0x00 0x46 0x00 0x47 0x00 0x48 0x00 0x49 0x00 0x4a 0x00 0x4b 0x00 0x4c 0x00 0x4d 0x00 0x4e 0x00 0x4f 0x00
			0x50 0x00 0x51 0x00 0x52 0x00 0x53 0x00 0x54 0x00 0x55 0x00 0x56 0x00 0x57 0x00 0x58 0x00 0x59 0x00 0x5a 0x00 0x5b 0x00
			0x5c 0x00 0x5d 0x00 0x5e 0x00 0x5f 0x00 0x60 0x00 0x61 0x00 0x62 0x00 0x63 0x00 0x64 0x00 0x65 0x80 0x66 0x00 0x67 0x00
			0x68 0x00 0x69 0x00 0x6a 0x00 0x6b 0x00 0x6c 0x00 0x6d 0x00 0x6e 0x00 0x6f 0x00 0x70 0x00 0x71 0x00 0x72 0x00 0x73 0x00
			0x74 0x00 0x75 0x00 0x76 0x00 0x77 0x00 0x78 0x00 0x79 0x00 0x7a 0x00 0x7b 0x00 0x7c 0x00 0x7d 0x00 0x7e 0x00 0x7f 0x00
			0x00 0x1f 0x08 0x00 0x09 0x00 0x0a 0x00 0x0b 0x00 0x0c 0x00 0x0d 0x00 0x0e 0x00 0x0f 0x00 0x10 0x00 0x11 0x00 0x12 0x00
			0x13 0x00 0x14 0x00 0x15 0x00 0x16 0x00 0x17 0x00 0x18 0x00 0x19 0x00 0x1a 0x00 0x1b 0x00 0x1c 0x00 0x1d 0x00 0x1e 0x00
			0x1f 0x00 0x20 0x00 0x21 0x00 0x22 0x00 0x23 0x00 0x24 0x00 0x25 0x00 0x26 0x00 0x27 0x00 0x28 0x00 0x29 0x00 0x2a 0x00
			0x2b 0x00 0x2c 0x00 0x2d 0x00 0x2e 0x03 0x2f 0xc0 0x30 0x00 0x31 0x00 0x32 0x04 0x33 0x00 0x34 0x00 0x35 0x00 0x36 0x04
			0x37 0x40 0x38 0x00 0x39 0x00 0x3a 0x00 0x3b 0x00 0x3c 0x00 0x3d 0x00 0x3e 0x00 0x3f 0x00 0x40 0x00 0x41 0x00 0x42 0x00
			0x43 0x00 0x44 0x00 0x45 0x00 0x46 0x00 0x47 0x00 0x48 0x00 0x49 0x00 0x4a 0x00 0x4b 0x00 0x4c 0x00 0x4d 0x00 0x4e 0x00
			0x4f 0x00 0x50 0x00 0x51 0x00 0x52 0x00 0x53 0x00 0x54 0x00 0x55 0x00 0x56 0x02 0x57 0x40 0x58 0x00 0x59 0x00 0x5a 0x02
			0x5b 0x80 0x5c 0x00 0x5d 0x00 0x5e 0x02 0x5f 0xc0 0x60 0x00 0x61 0x00 0x62 0x00 0x63 0x00 0x64 0x00 0x65 0x00 0x66 0x00
			0x67 0x00 0x68 0x00 0x69 0x00 0x6a 0x00 0x6b 0x00 0x6c 0x00 0x6d 0x00 0x6e 0x00 0x6f 0x00 0x70 0x00 0x71 0x00 0x72 0x00
			0x73 0x00 0x74 0x00 0x75 0x00 0x76 0x00 0x77 0x00 0x78 0x00 0x79 0x00 0x7a 0x00 0x7b 0x00 0x7c 0x00 0x7d 0x00 0x7e 0x00
			0x7f 0x00 0x00 0x20 0x08 0x00 0x09 0x00 0x0a 0x00 0x0b 0x00 0x0c 0x00 0x0d 0x00 0x0e 0x00 0x0f 0x00 0x10 0x00 0x11 0x00
			0x12 0x00 0x13 0x00 0x14 0x00 0x15 0x00 0x16 0x00 0x17 0x00 0x18 0x00 0x19 0x80 0x1a 0x00 0x1b 0x00 0x1c 0x00 0x1d 0x00
			0x1e 0x00 0x1f 0x00 0x20 0x00 0x21 0x00 0x22 0x00 0x23 0x00 0x24 0x00 0x25 0x00 0x26 0x00 0x27 0x00 0x28 0x00 0x29 0x00
			0x2a 0x00 0x2b 0x00 0x2c 0x00 0x2d 0x00 0x2e 0x0f 0x2f 0x00 0x30 0x00 0x31 0x00 0x32 0x00 0x33 0xff 0x34 0x00 0x35 0x00
			0x36 0x00 0x37 0x00 0x38 0x00 0x39 0x00 0x3a 0x00 0x3b 0x00 0x00 0x27 0x38 0x10 0x39 0x00 0x3a 0x00 0x3b 0x00 0x3c 0x10
			0x3d 0xf2 0x3e 0xb4 0x3f 0x08 0x40 0x11 0x41 0xf3 0x42 0xc9 0x43 0x9f 0x44 0x13 0x45 0x04 0x46 0x1a 0x47 0xe9 0x48 0x14
			0x49 0x24 0x4a 0x8e 0x4b 0xf8 0x4c 0x15 0x4d 0x56 0x4e 0x1a 0x4f 0x91 0x50 0x16 0x51 0x99 0x52 0xc0 0x53 0xf7 0x54 0x17
			0x55 0xf0 0x56 0x94 0x57 0xcc 0x58 0x19 0x59 0x5b 0x5a 0xb8 0x5b 0xf6 0x5c 0x1a 0x5d 0xdc 0x5e 0x61 0x5f 0x9a 0x60 0x1c
			0x61 0x73 0x62 0xd5 0x63 0x1c 0x64 0x1e 0x65 0x23 0x66 0x6d 0x67 0x3a 0x68 0x1f 0x69 0xec 0x6a 0x98 0x6b 0x2d 0x6c 0x21
			0x6d 0xd0 0x6e 0xd9 0x6f 0xe2 0x70 0x23 0x71 0xd1 0x72 0xcd 0x73 0x41 0x74 0x25 0x75 0xf1 0x76 0x25 0x77 0x8e 0x78 0x28
			0x79 0x30 0x7a 0xaf 0x7b 0xd3 0x7c 0x2a 0x7d 0x92 0x7e 0x54 0x7f 0x70 0x00 0x28 0x08 0x2d 0x09 0x18 0x0a 0x18 0x0b 0xb3
			0x0c 0x2f 0x0d 0xc4 0x0e 0x20 0x0f 0x90 0x10 0x32 0x11 0x98 0x12 0xb0 0x13 0x75 0x14 0x35 0x15 0x98 0x16 0x2f 0x17 0x34
			0x18 0x38 0x19 0xc5 0x1a 0x28 0x1b 0x0b 0x1c 0x3c 0x1d 0x22 0x1e 0x4c 0x1f 0xd2 0x20 0x3f 0x21 0xb2 0x22 0x78 0x23 0x3e
			0x24 0x43 0x25 0x78 0x26 0xb0 0x27 0x53 0x28 0x47 0x29 0x78 0x2a 0x28 0x2b 0xf1 0x2c 0x4b 0x2d 0xb4 0x2e 0x46 0x2f 0x8b
			0x30 0x50 0x31 0x30 0x32 0xa1 0x33 0x0c 0x34 0x54 0x35 0xf1 0x36 0x06 0x37 0xde 0x38 0x59 0x39 0xf9 0x3a 0x80 0x3b 0x2c
			0x3c 0x5f 0x3d 0x4e 0x3e 0x52 0x3f 0x47 0x00 0x00 0x7f 0x8c 0x00 0x0e 0x5c 0x00 0x5d 0x80 0x5e 0x00 0x5f 0x00 0x60 0x00
			0x61 0x80 0x62 0x00 0x63 0x00 0x64 0x00 0x65 0x80 0x66 0x00 0x67 0x00 0x68 0x08 0x69 0x00 0x6a 0x00 0x6b 0x00 0x6c 0x00
			0x6d 0x00 0x6e 0x00 0x6f 0x00 0x70 0x00 0x71 0x00 0x72 0x00 0x73 0x00 0x74 0x00 0x75 0x00 0x76 0x00 0x77 0x00 0x78 0x00
			0x79 0x00 0x7a 0x00 0x7b 0x00 0x7c 0x08 0x7d 0x00 0x7e 0x00 0x7f 0x00 0x00 0x0f 0x08 0x00 0x09 0x00 0x0a 0x00 0x0b 0x00
			0x0c 0x00 0x0d 0x00 0x0e 0x00 0x0f 0x00 0x10 0x00 0x11 0x00 0x12 0x00 0x13 0x00 0x14 0x00 0x15 0x00 0x16 0x00 0x17 0x00
			0x18 0x00 0x19 0x80 0x1a 0x00 0x1b 0x00 0x1c 0x00 0x1d 0x00 0x1e 0x00 0x1f 0x00 0x20 0x00 0x21 0x00 0x22 0x00 0x23 0x00
			0x24 0x20 0x25 0x00 0x26 0x00 0x27 0x00 0x28 0x20 0x29 0x00 0x2a 0x00 0x2b 0x00 0x2c 0x00 0x2d 0x00 0x2e 0x00 0x2f 0x3f
			0x30 0x00 0x31 0x00 0x32 0x00 0x33 0x3f 0x3c 0x00 0x3d 0x00 0x3e 0x00 0x3f 0x00 0x40 0x00 0x41 0x00 0x42 0x00 0x43 0x00
			0x44 0x00 0x45 0x00 0x46 0x01 0x47 0x80 0x48 0x7f 0x49 0xdf 0x4a 0x3b 0x4b 0x64 0x4c 0x79 0x4d 0x99 0x4e 0x99 0x4f 0x99
			0x50 0x05 0x51 0x38 0x52 0xef 0x53 0x34 0x54 0x65 0x55 0xac 0x56 0x8c 0x57 0x2f 0x58 0x50 0x59 0xc3 0x5a 0x35 0x5b 0xd3
			0x5c 0x40 0x5d 0x26 0x5e 0xe7 0x5f 0x3c 0x60 0x32 0x61 0xf5 0x62 0x2c 0x63 0xfe 0x64 0x28 0x65 0x7a 0x66 0x26 0x67 0xc4
			0x68 0x20 0x69 0x26 0x6a 0xf3 0x6b 0x0f 0x6c 0x19 0x6d 0x8a 0x6e 0x13 0x6f 0x57 0x70 0x14 0x71 0x49 0x72 0x60 0x73 0xc5
			0x74 0x10 0x75 0x1d 0x76 0x3f 0x77 0x2d 0x78 0x0c 0x79 0xcc 0x7a 0xcc 0x7b 0xcc 0x7c 0x0a 0x7d 0x2a 0x7e 0xda 0x7f 0xd1
			0x00 0x10 0x08 0x08 0x09 0x13 0x0a 0x85 0x0b 0x61 0x0c 0x08 0x0d 0x13 0x0e 0x85 0x0f 0x61 0x10 0x08 0x11 0x13 0x12 0x85
			0x13 0x61 0x14 0x08 0x15 0x13 0x16 0x85 0x17 0x61 0x18 0x08 0x19 0x13 0x1a 0x85 0x1b 0x61 0x1c 0x08 0x1d 0x00 0x1e 0x00
			0x1f 0x00 0x20 0x00 0x21 0x00 0x22 0x00 0x23 0x00 0x24 0x00 0x25 0x00 0x26 0x00 0x27 0x00 0x28 0x00 0x29 0x00 0x2a 0x00
			0x2b 0x00 0x2c 0x00 0x2d 0x00 0x2e 0x00 0x2f 0x00 0x30 0x08 0x31 0x00 0x32 0x00 0x33 0x00 0x34 0x00 0x35 0x00 0x36 0x00
			0x37 0x00 0x38 0x00 0x39 0x00 0x3a 0x00 0x3b 0x00 0x3c 0x00 0x3d 0x00 0x3e 0x00 0x3f 0x00 0x40 0x00 0x41 0x00 0x42 0x00
			0x43 0x00 0x44 0x08 0x45 0x00 0x46 0x00 0x47 0x00 0x48 0x00 0x49 0x00 0x4a 0x00 0x4b 0x00 0x4c 0x00 0x4d 0x00 0x4e 0x00
			0x4f 0x00 0x50 0x00 0x51 0x00 0x52 0x00 0x53 0x00 0x54 0x00 0x55 0x00 0x56 0x00 0x57 0x00 0x58 0x08 0x59 0x00 0x5a 0x00
			0x5b 0x00 0x5c 0x00 0x5d 0x00 0x5e 0x00 0x5f 0x00 0x60 0x00 0x61 0x00 0x62 0x00 0x63 0x00 0x64 0x00 0x65 0x00 0x66 0x00
			0x67 0x00 0x68 0x00 0x69 0x00 0x6a 0x00 0x6b 0x00 0x6c 0x08 0x6d 0x00 0x6e 0x00 0x6f 0x00 0x70 0x00 0x71 0x00 0x72 0x00
			0x73 0x00 0x74 0x00 0x75 0x00 0x76 0x00 0x77 0x00 0x78 0x00 0x79 0x00 0x7a 0x00 0x7b 0x00 0x7c 0x00 0x7d 0x00 0x7e 0x00
			0x7f 0x00 0x00 0x11 0x08 0x08 0x09 0x00 0x0a 0x00 0x0b 0x00 0x0c 0x00 0x0d 0x00 0x0e 0x00 0x0f 0x00 0x10 0x00 0x11 0x00
			0x12 0x00 0x13 0x00 0x14 0x00 0x15 0x00 0x16 0x00 0x17 0x00 0x18 0x00 0x19 0x00 0x1a 0x00 0x1b 0x00 0x1c 0x7f 0x1d 0xff
			0x1e 0xff 0x1f 0xff 0x20 0x7f 0x21 0xff 0x22 0xff 0x23 0xff 0x24 0x7f 0x25 0xff 0x26 0xff 0x27 0xff 0x28 0x00 0x29 0x00
			0x2a 0x00 0x2b 0x00 0x2c 0x00 0x2d 0x00 0x2e 0x00 0x2f 0x00 0x30 0x00 0x31 0x00 0x32 0x00 0x33 0x00 0x34 0xf9 0x35 0xda
			0x36 0xbc 0x37 0x21 0x38 0xfc 0x39 0x58 0x3a 0x8b 0x3b 0x89 0x3c 0x00 0x3d 0x00 0x3e 0x00 0x3f 0x00 0x40 0x00 0x41 0x00
			0x42 0x00 0x43 0x00 0x44 0x7f 0x45 0xff 0x46 0xff 0x47 0xff 0x48 0x7f 0x49 0xff 0x4a 0xff 0x4b 0xff 0x4c 0x7f 0x4d 0xff
			0x4e 0xff 0x4f 0xff 0x50 0x00 0x51 0x00 0x52 0x00 0x53 0x00 0x54 0x00 0x55 0x00 0x56 0x00 0x57 0x00 0x58 0x00 0x59 0x00
			0x5a 0x00 0x5b 0x00 0x5c 0xf9 0x5d 0xda 0x5e 0xbc 0x5f 0x21 0x60 0xfc 0x61 0x58 0x62 0x8b 0x63 0x89 0x64 0x00 0x65 0x00
			0x66 0x00 0x67 0x00 0x68 0x00 0x69 0x00 0x6a 0x00 0x6b 0x00 0x6c 0x7f 0x6d 0xff 0x6e 0xff 0x6f 0xff 0x70 0x7f 0x71 0xff
			0x72 0xff 0x73 0xff 0x74 0x7f 0x75 0xff 0x76 0xff 0x77 0xff 0x78 0x00 0x79 0x00 0x7a 0x00 0x7b 0x00 0x7c 0x00 0x7d 0x00
			0x7e 0x00 0x7f 0x00 0x00 0x12 0x08 0x00 0x09 0x00 0x0a 0x00 0x0b 0x00 0x0c 0xf9 0x0d 0xda 0x0e 0xbc 0x0f 0x21 0x10 0xfc
			0x11 0x58 0x12 0x8b 0x13 0x89 0x14 0x00 0x15 0x00 0x16 0x00 0x17 0x00 0x18 0x00 0x19 0x00 0x1a 0x00 0x1b 0x00 0x1c 0x10
			0x1d 0x00 0x1e 0x00 0x1f 0x00 0x20 0x00 0x21 0x00 0x22 0x00 0x23 0x07 0x24 0x00 0x25 0x00 0x26 0x04 0x27 0x00 0x28 0x00
			0x29 0x00 0x2a 0x00 0x2b 0x00 0x2c 0x00 0x2d 0x80 0x2e 0x00 0x2f 0x00 0x30 0x00 0x31 0x00 0x32 0x00 0x33 0x00 0x34 0xe7
			0x35 0x00 0x36 0x00 0x37 0x00 0x38 0xfe 0x39 0x80 0x3a 0x00 0x3b 0x00 0x3c 0x00 0x3d 0x00 0x3e 0x00 0x3f 0x00 0x40 0x00
			0x41 0x00 0x42 0x00 0x43 0x00 0x00 0x00 0x7f 0x00 0x40 0x00 0x4c 0x2f 0x33 0x03 0x50 0x00 0x00 0x00 0x7f 0x00 0x7d 0x11
			0x7e 0xff 0x00 0x01 0x51 0x05 0x00 0x02 0x19 0xdf 0x00 0x00 0x7f 0x8c 0x00 0x07 0x74 0x40 0x75 0x00 0x76 0x00 0x77 0x00
			0x00 0x00 0x7f 0x8c 0x00 0x0a 0x64 0x00 0x65 0x00 0x66 0x00 0x67 0x00 0x70 0x00 0x71 0x00 0x72 0x00 0x73 0x00 0x00 0x00
			0x7f 0x8c 0x00 0x0b 0x74 0x00 0x75 0x08 0x76 0x00 0x77 0x00 0x78 0x00 0x79 0x08 0x7a 0x00 0x7b 0x00 0x00 0x00 0x7f 0x00
			0x46 0x09 0x00 0x00 0x02 0x00 0x53 0x20 0x54 0x0c 0x00 0x00 0x7f 0x00 0x03 0x02 0x00 0x00 0x7f 0x8c 0x00 0x0b 0x50 0x00
			0x51 0x20 0x52 0xc4 0x53 0x9c 0x5c 0x7f 0x5d 0xff 0x5e 0xff 0x5f 0xff 0x7c 0x00 0x7d 0x00 0x7e 0x00 0x7f 0x00 0x00 0x0c
			0x08 0x00 0x09 0x00 0x0a 0x00 0x0b 0x00 0x00 0x00 0x7f 0x8c 0x00 0x01 0x28 0x40 0x29 0x00 0x2a 0x00 0x2b 0x00 0x2c 0x00
			0x2d 0xe2 0x2e 0xc4 0x2f 0x6b 0x00 0x0a 0x74 0x00 0x75 0x78 0x76 0xd6 0x77 0xfd 0x78 0x00 0x79 0x00 0x7a 0x00 0x7b 0x00
			0x7c 0x00 0x7d 0x00 0x7e 0x00 0x7f 0x00 0x00 0x0b 0x08 0x00 0x09 0x78 0x0a 0xd6 0x0b 0xfd 0x0c 0x00 0x0d 0x80 0x0e 0x00
			0x0f 0x00 0x10 0x00 0x11 0x80 0x12 0x00 0x13 0x00 0x14 0x00 0x15 0x00 0x16 0x00 0x17 0x00 0x18 0x00 0x19 0x78 0x1a 0xd6
			0x1b 0xfd 0x1c 0x00 0x1d 0x78 0x1e 0xd6 0x1f 0xfd 0x20 0x00 0x21 0x00 0x22 0x00 0x23 0x00 0x28 0x00 0x29 0x00 0x2a 0x00
			0x2b 0x01 0x2c 0x00 0x2d 0x00 0x2e 0x00 0x2f 0x01 0x30 0x00 0x31 0x00 0x32 0xae 0x33 0xc3 0x34 0x00 0x35 0x00 0x36 0x00
			0x37 0x00 0x48 0x04 0x49 0xc1 0x4a 0xff 0x4b 0x93 0x4c 0x00 0x4d 0x45 0x4e 0xa1 0x4f 0xcb 0x54 0x7b 0x55 0x3e 0x56 0x00
			0x57 0x6d 0x58 0x00 0x59 0x00 0x5a 0xae 0x5b 0xc3 0x60 0x08 0x61 0x13 0x62 0x85 0x63 0x62 0x64 0x00 0x65 0x80 0x66 0x00
			0x67 0x00 0x6c 0x00 0x6d 0x3c 0x6e 0x90 0x6f 0x38 0x70 0x00 0x71 0x08 0x72 0x13 0x73 0x85 0x00 0x0f 0x24 0x02 0x25 0xa3
			0x26 0x9a 0x27 0xcc 0x28 0x00 0x29 0x06 0x2a 0xd3 0x2b 0x72 0x2c 0x00 0x2d 0x00 0x2e 0x00 0x2f 0x3f 0x30 0x00 0x31 0x00
			0x32 0x00 0x33 0x3f 0x40 0x00 0x41 0x00 0x42 0x00 0x43 0x00 0x44 0x00 0x45 0x00 0x46 0x01 0x47 0xe0 0x48 0x7f 0x49 0xdf
			0x4a 0x3b 0x4b 0x64 0x4c 0x79 0x4d 0x99 0x4e 0x99 0x4f 0x9a 0x50 0x05 0x51 0x39 0x52 0x47 0x53 0xa6 0x54 0x05 0x55 0xdf
			0x56 0x3b 0x57 0x64 0x58 0x05 0x59 0xa5 0x5a 0xe3 0x5b 0x54 0x5c 0x05 0x5d 0x6c 0x5e 0x8b 0x5f 0x44 0x60 0x05 0x61 0x33
			0x62 0x33 0x63 0x33 0x64 0x04 0x65 0xf9 0x66 0xdb 0x67 0x23 0x68 0x04 0x69 0xc0 0x6a 0x83 0x6b 0x12 0x6c 0x04 0x6d 0x87
			0x6e 0x2b 0x6f 0x02 0x70 0x04 0x71 0x4d 0x72 0xd2 0x73 0xf2 0x74 0x04 0x75 0x14 0x76 0x7a 0x77 0xe1 0x78 0x03 0x79 0xdb
			0x7a 0x22 0x7b 0xd1 0x7c 0x03 0x7d 0xa1 0x7e 0xca 0x7f 0xc1 0x00 0x10 0x08 0x03 0x09 0x68 0x0a 0x72 0x0b 0xb0 0x0c 0x03
			0x0d 0x2f 0x0e 0x1a 0x0f 0xa0 0x10 0x02 0x11 0xf5 0x12 0xc2 0x13 0x8f 0x14 0x02 0x15 0xbc 0x16 0x6a 0x17 0x7f 0x18 0x02
			0x19 0x83 0x1a 0x12 0x1b 0x6f 0x00 0x00 0x7f 0xaa 0x00 0x01 0x30 0x08 0x31 0x00 0x32 0x00 0x33 0x00 0x34 0x00 0x35 0x00
			0x36 0x00 0x37 0x00 0x38 0x00 0x39 0x00 0x3a 0x00 0x3b 0x00 0x3c 0x00 0x3d 0x00 0x3e 0x00 0x3f 0x00 0x40 0x00 0x41 0x00
			0x42 0x00 0x43 0x00 0x44 0x08 0x45 0x00 0x46 0x00 0x47 0x00 0x48 0x00 0x49 0x00 0x4a 0x00 0x4b 0x00 0x4c 0x00 0x4d 0x00
			0x4e 0x00 0x4f 0x00 0x50 0x00 0x51 0x00 0x52 0x00 0x53 0x00 0x54 0x00 0x55 0x00 0x56 0x00 0x57 0x00 0x58 0x08 0x59 0x00
			0x5a 0x00 0x5b 0x00 0x5c 0x00 0x5d 0x00 0x5e 0x00 0x5f 0x00 0x60 0x00 0x61 0x00 0x62 0x00 0x63 0x00 0x64 0x00 0x65 0x00
			0x66 0x00 0x67 0x00 0x68 0x00 0x69 0x00 0x6a 0x00 0x6b 0x00 0x6c 0x08 0x6d 0x00 0x6e 0x00 0x6f 0x00 0x70 0x00 0x71 0x00
			0x72 0x00 0x73 0x00 0x74 0x00 0x75 0x00 0x76 0x00 0x77 0x00 0x78 0x00 0x79 0x00 0x7a 0x00 0x7b 0x00 0x7c 0x00 0x7d 0x00
			0x7e 0x00 0x7f 0x00 0x00 0x02 0x08 0x08 0x09 0x00 0x0a 0x00 0x0b 0x00 0x0c 0x00 0x0d 0x00 0x0e 0x00 0x0f 0x00 0x10 0x00
			0x11 0x00 0x12 0x00 0x13 0x00 0x14 0x00 0x15 0x00 0x16 0x00 0x17 0x00 0x18 0x00 0x19 0x00 0x1a 0x00 0x1b 0x00 0x1c 0x08
			0x1d 0x00 0x1e 0x00 0x1f 0x00 0x20 0x00 0x21 0x00 0x22 0x00 0x23 0x00 0x24 0x00 0x25 0x00 0x26 0x00 0x27 0x00 0x28 0x00
			0x29 0x00 0x2a 0x00 0x2b 0x00 0x2c 0x00 0x2d 0x00 0x2e 0x00 0x2f 0x00 0x30 0x08 0x31 0x00 0x32 0x00 0x33 0x00 0x34 0x00
			0x35 0x00 0x36 0x00 0x37 0x00 0x38 0x00 0x39 0x00 0x3a 0x00 0x3b 0x00 0x3c 0x00 0x3d 0x00 0x3e 0x00 0x3f 0x00 0x40 0x00
			0x41 0x00 0x42 0x00 0x43 0x00 0x44 0x08 0x45 0x00 0x46 0x00 0x47 0x00 0x48 0x00 0x49 0x00 0x4a 0x00 0x4b 0x00 0x4c 0x00
			0x4d 0x00 0x4e 0x00 0x4f 0x00 0x50 0x00 0x51 0x00 0x52 0x00 0x53 0x00 0x54 0x00 0x55 0x00 0x56 0x00 0x57 0x00 0x58 0x08
			0x59 0x00 0x5a 0x00 0x5b 0x00 0x5c 0x00 0x5d 0x00 0x5e 0x00 0x5f 0x00 0x60 0x00 0x61 0x00 0x62 0x00 0x63 0x00 0x64 0x00
			0x65 0x00 0x66 0x00 0x67 0x00 0x68 0x00 0x69 0x00 0x6a 0x00 0x6b 0x00 0x6c 0x08 0x6d 0x00 0x6e 0x00 0x6f 0x00 0x70 0x00
			0x71 0x00 0x72 0x00 0x73 0x00 0x74 0x00 0x75 0x00 0x76 0x00 0x77 0x00 0x78 0x00 0x79 0x00 0x7a 0x00 0x7b 0x00 0x7c 0x00
			0x7d 0x00 0x7e 0x00 0x7f 0x00 0x00 0x03 0x08 0x08 0x09 0x00 0x0a 0x00 0x0b 0x00 0x0c 0x00 0x0d 0x00 0x0e 0x00 0x0f 0x00
			0x10 0x00 0x11 0x00 0x12 0x00 0x13 0x00 0x14 0x00 0x15 0x00 0x16 0x00 0x17 0x00 0x18 0x00 0x19 0x00 0x1a 0x00 0x1b 0x00
			0x1c 0x08 0x1d 0x00 0x1e 0x00 0x1f 0x00 0x20 0x00 0x21 0x00 0x22 0x00 0x23 0x00 0x24 0x00 0x25 0x00 0x26 0x00 0x27 0x00
			0x28 0x00 0x29 0x00 0x2a 0x00 0x2b 0x00 0x2c 0x00 0x2d 0x00 0x2e 0x00 0x2f 0x00 0x30 0x08 0x31 0x00 0x32 0x00 0x33 0x00
			0x34 0x00 0x35 0x00 0x36 0x00 0x37 0x00 0x38 0x00 0x39 0x00 0x3a 0x00 0x3b 0x00 0x3c 0x00 0x3d 0x00 0x3e 0x00 0x3f 0x00
			0x40 0x00 0x41 0x00 0x42 0x00 0x43 0x00 0x44 0x08 0x45 0x00 0x46 0x00 0x47 0x00 0x48 0x00 0x49 0x00 0x4a 0x00 0x4b 0x00
			0x4c 0x00 0x4d 0x00 0x4e 0x00 0x4f 0x00 0x50 0x00 0x51 0x00 0x52 0x00 0x53 0x00 0x54 0x00 0x55 0x00 0x56 0x00 0x57 0x00
			0x58 0x08 0x59 0x00 0x5a 0x00 0x5b 0x00 0x5c 0x00 0x5d 0x00 0x5e 0x00 0x5f 0x00 0x60 0x00 0x61 0x00 0x62 0x00 0x63 0x00
			0x64 0x00 0x65 0x00 0x66 0x00 0x67 0x00 0x68 0x00 0x69 0x00 0x6a 0x00 0x6b 0x00 0x6c 0x08 0x6d 0x00 0x6e 0x00 0x6f 0x00
			0x70 0x00 0x71 0x00 0x72 0x00 0x73 0x00 0x74 0x00 0x75 0x00 0x76 0x00 0x77 0x00 0x78 0x00 0x79 0x00 0x7a 0x00 0x7b 0x00
			0x7c 0x00 0x7d 0x00 0x7e 0x00 0x7f 0x00 0x00 0x04 0x08 0x08 0x09 0x00 0x0a 0x00 0x0b 0x00 0x0c 0x00 0x0d 0x00 0x0e 0x00
			0x0f 0x00 0x10 0x00 0x11 0x00 0x12 0x00 0x13 0x00 0x14 0x00 0x15 0x00 0x16 0x00 0x17 0x00 0x18 0x00 0x19 0x00 0x1a 0x00
			0x1b 0x00 0x1c 0x08 0x1d 0x00 0x1e 0x00 0x1f 0x00 0x20 0x00 0x21 0x00 0x22 0x00 0x23 0x00 0x24 0x00 0x25 0x00 0x26 0x00
			0x27 0x00 0x28 0x00 0x29 0x00 0x2a 0x00 0x2b 0x00 0x2c 0x00 0x2d 0x00 0x2e 0x00 0x2f 0x00 0x30 0x08 0x31 0x00 0x32 0x00
			0x33 0x00 0x34 0x00 0x35 0x00 0x36 0x00 0x37 0x00 0x38 0x00 0x39 0x00 0x3a 0x00 0x3b 0x00 0x3c 0x00 0x3d 0x00 0x3e 0x00
			0x3f 0x00 0x40 0x00 0x41 0x00 0x42 0x00 0x43 0x00 0x44 0x08 0x45 0x00 0x46 0x00 0x47 0x00 0x48 0x00 0x49 0x00 0x4a 0x00
			0x4b 0x00 0x4c 0x00 0x4d 0x00 0x4e 0x00 0x4f 0x00 0x50 0x00 0x51 0x00 0x52 0x00 0x53 0x00 0x54 0x00 0x55 0x00 0x56 0x00
			0x57 0x00 0x58 0x08 0x59 0x00 0x5a 0x00 0x5b 0x00 0x5c 0x00 0x5d 0x00 0x5e 0x00 0x5f 0x00 0x60 0x00 0x61 0x00 0x62 0x00
			0x63 0x00 0x64 0x00 0x65 0x00 0x66 0x00 0x67 0x00 0x68 0x00 0x69 0x00 0x6a 0x00 0x6b 0x00 0x6c 0x08 0x6d 0x00 0x6e 0x00
			0x6f 0x00 0x70 0x00 0x71 0x00 0x72 0x00 0x73 0x00 0x74 0x00 0x75 0x00 0x76 0x00 0x77 0x00 0x78 0x00 0x79 0x00 0x7a 0x00
			0x7b 0x00 0x7c 0x00 0x7d 0x00 0x7e 0x00 0x7f 0x00 0x00 0x05 0x08 0x08 0x09 0x00 0x0a 0x00 0x0b 0x00 0x0c 0x00 0x0d 0x00
			0x0e 0x00 0x0f 0x00 0x10 0x00 0x11 0x00 0x12 0x00 0x13 0x00 0x14 0x00 0x15 0x00 0x16 0x00 0x17 0x00 0x18 0x00 0x19 0x00
			0x1a 0x00 0x1b 0x00 0x1c 0x08 0x1d 0x00 0x1e 0x00 0x1f 0x00 0x20 0x00 0x21 0x00 0x22 0x00 0x23 0x00 0x24 0x00 0x25 0x00
			0x26 0x00 0x27 0x00 0x28 0x00 0x29 0x00 0x2a 0x00 0x2b 0x00 0x2c 0x00 0x2d 0x00 0x2e 0x00 0x2f 0x00 0x30 0x08 0x31 0x00
			0x32 0x00 0x33 0x00 0x34 0x00 0x35 0x00 0x36 0x00 0x37 0x00 0x38 0x00 0x39 0x00 0x3a 0x00 0x3b 0x00 0x3c 0x00 0x3d 0x00
			0x3e 0x00 0x3f 0x00 0x40 0x00 0x41 0x00 0x42 0x00 0x43 0x00 0x44 0x08 0x45 0x00 0x46 0x00 0x47 0x00 0x48 0x00 0x49 0x00
			0x4a 0x00 0x4b 0x00 0x4c 0x00 0x4d 0x00 0x4e 0x00 0x4f 0x00 0x50 0x00 0x51 0x00 0x52 0x00 0x53 0x00 0x54 0x00 0x55 0x00
			0x56 0x00 0x57 0x00 0x58 0x08 0x59 0x00 0x5a 0x00 0x5b 0x00 0x5c 0x00 0x5d 0x00 0x5e 0x00 0x5f 0x00 0x60 0x00 0x61 0x00
			0x62 0x00 0x63 0x00 0x64 0x00 0x65 0x00 0x66 0x00 0x67 0x00 0x68 0x00 0x69 0x00 0x6a 0x00 0x6b 0x00 0x6c 0x08 0x6d 0x00
			0x6e 0x00 0x6f 0x00 0x70 0x00 0x71 0x00 0x72 0x00 0x73 0x00 0x74 0x00 0x75 0x00 0x76 0x00 0x77 0x00 0x78 0x00 0x79 0x00
			0x7a 0x00 0x7b 0x00 0x7c 0x00 0x7d 0x00 0x7e 0x00 0x7f 0x00 0x00 0x06 0x08 0x08 0x09 0x00 0x0a 0x00 0x0b 0x00 0x0c 0x00
			0x0d 0x00 0x0e 0x00 0x0f 0x00 0x10 0x00 0x11 0x00 0x12 0x00 0x13 0x00 0x14 0x00 0x15 0x00 0x16 0x00 0x17 0x00 0x18 0x00
			0x19 0x00 0x1a 0x00 0x1b 0x00 0x1c 0x08 0x1d 0x00 0x1e 0x00 0x1f 0x00 0x20 0x00 0x21 0x00 0x22 0x00 0x23 0x00 0x24 0x00
			0x25 0x00 0x26 0x00 0x27 0x00 0x28 0x00 0x29 0x00 0x2a 0x00 0x2b 0x00 0x2c 0x00 0x2d 0x00 0x2e 0x00 0x2f 0x00 0x00 0x00
			0x7f 0x78 0x00 0x1d 0x30 0x00 0x31 0x00 0x32 0x00 0x33 0x00 0x34 0x00 0x35 0x01 0x36 0x00 0x37 0x01 0x38 0x00 0x39 0x03
			0x3a 0x00 0x3b 0x03 0x3c 0x00 0x3d 0x07 0x3e 0x00 0x3f 0x07 0x40 0x00 0x41 0x0f 0x42 0x00 0x43 0x0f 0x44 0x00 0x45 0x1f
			0x46 0x00 0x47 0x1f 0x48 0x00 0x49 0x3f 0x4a 0x00 0x4b 0x3f 0x4c 0x00 0x4d 0x7f 0x4e 0x00 0x4f 0x7f 0x50 0x00 0x51 0xff
			0x52 0x00 0x53 0xff 0x54 0x01 0x55 0xff 0x56 0x01 0x57 0xff 0x58 0x03 0x59 0xff 0x5a 0x03 0x5b 0xff 0x5c 0x07 0x5d 0xff
			0x5e 0x07 0x5f 0xff 0x60 0x0f 0x61 0xff 0x62 0x0f 0x63 0xff 0x64 0x1f 0x65 0xff 0x66 0x1f 0x67 0xff 0x68 0x3f 0x69 0xff
			0x6a 0x3f 0x6b 0xff 0x6c 0x7f 0x6d 0xff 0x6e 0x7f 0x6f 0xff 0x70 0xff 0x71 0xff 0x72 0xff 0x73 0xff 0x00 0x00 0x7f 0x8c
			0x00 0x07 0x64 0x00 0x65 0x80 0x66 0x00 0x67 0x00 0x6c 0x40 0x6d 0x00 0x6e 0x00 0x6f 0x00 0x70 0x40 0x71 0x00 0x72 0x00
			0x73 0x00 0x00 0x0f 0x18 0x00 0x19 0x80 0x1a 0x00 0x1b 0x00 0x20 0x00 0x21 0x00 0x22 0x00 0x23 0x00 0x1c 0x00 0x1d 0x00
			0x1e 0x00 0x1f 0x00 0x00 0x11 0x1c 0x00 0x1d 0x1b 0x1e 0x4b 0x1f 0x98 0x20 0x00 0x21 0x1b 0x22 0x4b 0x23 0x98 0x24 0x00
			0x25 0x0d 0x26 0xa6 0x27 0x86 0x28 0x00 0x29 0x00 0x2a 0x00 0x2b 0x00 0x2c 0x00 0x2d 0x00 0x2e 0x00 0x2f 0x00 0x30 0xff
			0x31 0x81 0x32 0x47 0x33 0xae 0x34 0xf9 0x35 0x06 0x36 0x21 0x37 0xa9 0x38 0xfe 0x39 0x01 0x3a 0xc0 0x3b 0x79 0x3c 0x00
			0x3d 0x00 0x3e 0x00 0x3f 0x00 0x40 0x00 0x41 0x00 0x42 0x00 0x43 0x00 0x44 0x02 0x45 0xa3 0x46 0x9a 0x47 0xcc 0x48 0x02
			0x49 0xa3 0x4a 0x9a 0x4b 0xcc 0x4c 0x00 0x4d 0x06 0x4e 0xd3 0x4f 0x72 0x50 0x00 0x51 0x00 0x52 0x00 0x53 0x00 0x54 0x00
			0x55 0x00 0x56 0x00 0x57 0x00 0x58 0xff 0x59 0x81 0x5a 0x47 0x5b 0xae 0x5c 0xf9 0x5d 0x06 0x5e 0x21 0x5f 0xa9 0x60 0xfe
			0x61 0x01 0x62 0xc0 0x63 0x79 0x64 0x00 0x65 0x00 0x66 0x00 0x67 0x00 0x68 0x00 0x69 0x00 0x6a 0x00 0x6b 0x00 0x6c 0x02
			0x6d 0xa3 0x6e 0x9a 0x6f 0xcc 0x70 0x02 0x71 0xa3 0x72 0x9a 0x73 0xcc 0x74 0x00 0x75 0x44 0x76 0x32 0x77 0x13 0x78 0x00
			0x79 0x00 0x7a 0x00 0x7b 0x00 0x7c 0x00 0x7d 0x00 0x7e 0x00 0x7f 0x00 0x00 0x12 0x08 0xff 0x09 0x81 0x0a 0x47 0x0b 0xae
			0x0c 0xf9 0x0d 0x06 0x0e 0x21 0x0f 0xa9 0x10 0xfe 0x11 0x01 0x12 0xc0 0x13 0x79 0x14 0x00 0x15 0x00 0x16 0x00 0x17 0x00
			0x18 0x00 0x19 0x00 0x1a 0x00 0x1b 0x00 0x00 0x00 0x7f 0xaa 0x00 0x0e 0x68 0x08 0x69 0x00 0x6a 0x00 0x6b 0x00 0x6c 0x00
			0x6d 0x00 0x6e 0x00 0x6f 0x00 0x70 0x00 0x71 0x00 0x72 0x00 0x73 0x00 0x74 0x00 0x75 0x00 0x76 0x00 0x77 0x00 0x78 0x00
			0x79 0x00 0x7a 0x00 0x7b 0x00 0x00 0x11 0x08 0x08 0x09 0x00 0x0a 0x00 0x0b 0x00 0x0c 0x00 0x0d 0x00 0x0e 0x00 0x0f 0x00
			0x10 0x00 0x11 0x00 0x12 0x00 0x13 0x00 0x14 0x00 0x15 0x00 0x16 0x00 0x17 0x00 0x18 0x00 0x19 0x00 0x1a 0x00 0x1b 0x00
			0x00 0x10 0x1c 0x08 0x1d 0x00 0x1e 0x00 0x1f 0x00 0x20 0x00 0x21 0x00 0x22 0x00 0x23 0x00 0x24 0x00 0x25 0x00 0x26 0x00
			0x27 0x00 0x28 0x00 0x29 0x00 0x2a 0x00 0x2b 0x00 0x2c 0x00 0x2d 0x00 0x2e 0x00 0x2f 0x00 0x30 0x08 0x31 0x00 0x32 0x00
			0x33 0x00 0x34 0x00 0x35 0x00 0x36 0x00 0x37 0x00 0x38 0x00 0x39 0x00 0x3a 0x00 0x3b 0x00 0x3c 0x00 0x3d 0x00 0x3e 0x00
			0x3f 0x00 0x40 0x00 0x41 0x00 0x42 0x00 0x43 0x00 0x44 0x08 0x45 0x00 0x46 0x00 0x47 0x00 0x48 0x00 0x49 0x00 0x4a 0x00
			0x4b 0x00 0x4c 0x00 0x4d 0x00 0x4e 0x00 0x4f 0x00 0x50 0x00 0x51 0x00 0x52 0x00 0x53 0x00 0x54 0x00 0x55 0x00 0x56 0x00
			0x57 0x00 0x58 0x08 0x59 0x00 0x5a 0x00 0x5b 0x00 0x5c 0x00 0x5d 0x00 0x5e 0x00 0x5f 0x00 0x60 0x00 0x61 0x00 0x62 0x00
			0x63 0x00 0x64 0x00 0x65 0x00 0x66 0x00 0x67 0x00 0x68 0x00 0x69 0x00 0x6a 0x00 0x6b 0x00 0x6c 0x08 0x6d 0x00 0x6e 0x00
			0x6f 0x00 0x70 0x00 0x71 0x00 0x72 0x00 0x73 0x00 0x74 0x00 0x75 0x00 0x76 0x00 0x77 0x00 0x78 0x00 0x79 0x00 0x7a 0x00
			0x7b 0x00 0x7c 0x00 0x7d 0x00 0x7e 0x00 0x7f 0x00 0x00 0x0e 0x7c 0x08 0x7d 0x00 0x7e 0x00 0x7f 0x00 0x00 0x0f 0x08 0x00
			0x09 0x00 0x0a 0x00 0x0b 0x00 0x0c 0x00 0x0d 0x00 0x0e 0x00 0x0f 0x00 0x10 0x00 0x11 0x00 0x12 0x00 0x13 0x00 0x14 0x00
			0x15 0x00 0x16 0x00 0x17 0x00 0x00 0x00 0x7f 0x00 0x30 0x00 0x60 0x07 0x61 0x0b 0x62 0x09 0x63 0x08 0x64 0x00 0x41 0x1f
			0x4c 0x2f 0x03 0x03 0x00 0x00 0x7f 0x00 0x78 0x80 >;
		init-sequence-length3 = <14>;
		reg-init3 = < 0x00 0x00 0x7f 0x00 0x30 0x00 0x60 0x07 0x61 0x0b 0x62 0x09 0x63 0x08 0x64 0x00 0x41 0x1f 0x4c 0x2f
				 0x03 0x03 0x00 0x00 0x7f 0x00 0x78 0x80 >;
		status = "okay";
	};

	nxp-nt3h211@04 {       // NXP 3H2111 NFC
		compatible = "fsl,nxp-nt3h2111";
		reg = <0x04>;
		uses-alternate-address = <0x04>;
		status = "okay";
	};
};

&audiobus {

	aml_tdmb: tdmb {
		compatible = "amlogic, axg-snd-tdmb";
		#sound-dai-cells = <0>;
		dai-tdm-lane-slot-mask-out = <1>;
		dai-tdm-clk-sel = <1>;
		clocks = <&clkaudio CLKID_AUDIO_MCLK_B
				&clkc CLKID_MPLL1>;
		clock-names = "mclk", "clk_srcpll";
		pinctrl-names = "tdm_pins";
		pinctrl-0 = <&tdmout_b>;
		status = "okay";
	};

	aml_pdm: pdm {
		compatible = "amlogic, axg-snd-pdm";
		#sound-dai-cells = <0>;
		clocks = <&clkaudio CLKID_AUDIO_PDM
			&clkc CLKID_FCLK_DIV3
			&clkc CLKID_MPLL3
			&clkaudio CLKID_AUDIO_PDMIN0
			&clkaudio CLKID_AUDIO_PDMIN1>;
		clock-names = "gate",
			"sysclk_srcpll",
			"dclk_srcpll",
			"pdm_dclk",
			"pdm_sysclk";
		pinctrl-names = "pdm_pins";
		pinctrl-0 = <&pdmin>;
		filter_mode = <1>; /* mode 0~4, defalut:1 */
		status = "okay";
	};
}; /* end of audiobus */

&pinctrl_periphs {
	tdmout_a: tdmout_a {
		mux {
			groups = "tdma_sclk",
				"tdma_fs";
			function = "tdma_out";
		};
	};

	tdmout_a_data: tdmout_a_data {
		mux {
			groups = "tdma_dout1_x15";
			function = "tdma_out";
		};
	};

	tdmin_a: tdmin_a {
		mux {
			groups = "tdma_din0";
			function = "tdma_in";
		};
	};

	tdmb_mclk: tdmb_mclk {
		mux {
			groups = "mclk_b";
			function = "mclk_b";
		};
	};

	tdmout_b: tdmout_b {
		mux {
			groups = "tdmb_sclk",
				"tdmb_fs",
				"tdmb_dout0";
			function = "tdmb_out";
		};
	};

	tdmin_b:tdmin_b {
		mux {
			groups = "tdmb_din0",
				"tdmb_din1",
				"tdmb_din2_a12",
				"tdmb_din3_a13";
			function = "tdmb_in";
		};
	};

	tdmc_mclk: tdmc_mclk {
		mux {
			groups = "mclk_a";
			function = "mclk";
		};
	};

	tdmout_c:tdmout_c {
		mux {
			groups = "tdmc_sclk",
				"tdmc_fs",
				"tdmc_dout0",
				"tdmc_dout2_a6",
				"tdmc_dout3_a7";
			function = "tdmc_out";
		};
	};


	tdmin_c:tdmin_c {
		mux {
			groups = "tdmc_din1";
			function = "tdmc_in";
		};
	};

	spdifout: spidfout {
		mux {
			groups = "spdif_out_a20";
			function = "spdif_out";
		};
	};

	spdifin: spidfin {
		mux {
			groups = "spdif_in_a19";
			function = "spdif_in";
		};
	};

	pdmin: pdmin {
		mux {
			groups = "pdm_dclk_a14",
				"pdm_din0",
				"pdm_din1",
				"pdm_din2",
				"pdm_din3";
			function = "pdm";
		};
	};
}; /* end of pinctrl_periphs */

/* Audio Related End */

&pinctrl_aobus {
	boost_pwm_pins: boost_pwm_pins {
		mux {
			groups = "pwm_ao_a";
			function = "pwm_ao_a";
		};
	};
}; /* end of pinctrl_aobus */

&aobus{
	uart_AO: serial@3000 {
		compatible = "amlogic, meson-uart";
		reg = <0x0 0x3000 0x0 0x18>;
		interrupts = <0 193 1>;
		status = "okay";
		clocks = <&xtal>;
		clock-names = "clk_uart";
		xtal_tick_en = <1>;
		fifosize = < 64 >;
		pinctrl-names = "default";
		pinctrl-0 = <&ao_uart_pins>;
		support-sysrq = <1>;	/* 0 not support , 1 support */
	};

	uart_AO_B: serial@4000 {
		status = "disable";
		compatible = "amlogic, meson-uart";
		reg = <0x0 0x4000 0x0 0x18>;
		interrupts = <0 197 1>;
		clocks = <&xtal>;
		clock-names = "clk_uart";
		fifosize = < 64 >;
		pinctrl-names = "default";
		pinctrl-0 = <>;
	};
};

&audio_data{
	status = "okay";
};
